AUTOSAR XML (schema 3.1.2)
package /Components/SWC_ProdElEm
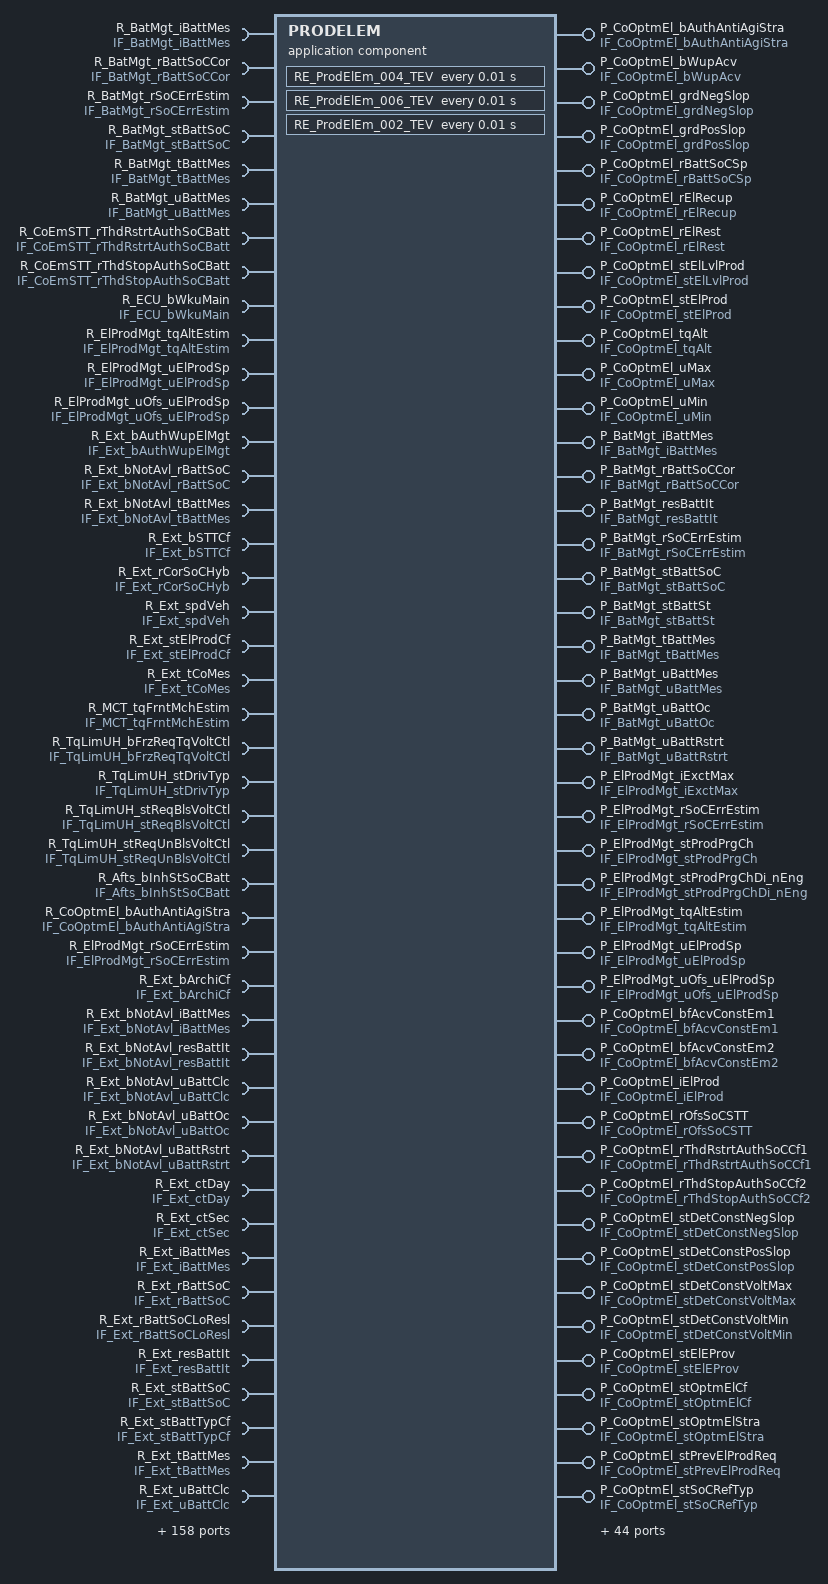
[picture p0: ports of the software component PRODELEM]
  application software component type PRODELEM
    189 x require port:
      R_BatMgt_iBattMes: unqueued-receiver-com-spec{data-element=BatMgt_iBattMes, init-value=ConstantValue, resync-time=0}, required-interface=IF_BatMgt_iBattMes
      R_BatMgt_rBattSoCCor: unqueued-receiver-com-spec{data-element=BatMgt_rBattSoCCor, init-value=ConstantValue1, resync-time=0}, required-interface=IF_BatMgt_rBattSoCCor
      R_BatMgt_rSoCErrEstim: unqueued-receiver-com-spec{data-element=BatMgt_rSoCErrEstim, init-value=BatMgt_rSoCErrEstim_in, resync-time=0}, required-interface=IF_BatMgt_rSoCErrEstim
      R_BatMgt_stBattSoC: unqueued-receiver-com-spec{data-element=BatMgt_stBattSoC, init-value=ConstantValue3, resync-time=0}, required-interface=IF_BatMgt_stBattSoC
      R_BatMgt_tBattMes: unqueued-receiver-com-spec{data-element=BatMgt_tBattMes, init-value=ConstantValue5, resync-time=0}, required-interface=IF_BatMgt_tBattMes
      R_BatMgt_uBattMes: unqueued-receiver-com-spec{data-element=BatMgt_uBattMes, init-value=ConstantValue7, resync-time=0}, required-interface=IF_BatMgt_uBattMes
      R_CoEmSTT_rThdRstrtAuthSoCBatt: unqueued-receiver-com-spec{data-element=CoEmSTT_rThdRstrtAuthSoCBatt, init-value=ConstantValue9, resync-time=0}, required-interface=IF_CoEmSTT_rThdRstrtAuthSoCBatt
      R_CoEmSTT_rThdStopAuthSoCBatt: unqueued-receiver-com-spec{data-element=CoEmSTT_rThdStopAuthSoCBatt, init-value=ConstantValue11, resync-time=0}, required-interface=IF_CoEmSTT_rThdStopAuthSoCBatt
      R_ECU_bWkuMain: unqueued-receiver-com-spec{data-element=ECU_bWkuMain, init-value=ConstantValue13, resync-time=0}, required-interface=IF_ECU_bWkuMain
      R_ElProdMgt_tqAltEstim: unqueued-receiver-com-spec{data-element=ElProdMgt_tqAltEstim, init-value=ElProdMgt_tqAltEstim_in, resync-time=0}, required-interface=IF_ElProdMgt_tqAltEstim
      R_ElProdMgt_uElProdSp: unqueued-receiver-com-spec{data-element=ElProdMgt_uElProdSp, init-value=ElProdMgt_uElProdSp_in, resync-time=0}, required-interface=IF_ElProdMgt_uElProdSp
      R_ElProdMgt_uOfs_uElProdSp: unqueued-receiver-com-spec{data-element=ElProdMgt_uOfs_uElProdSp, init-value=ElProdMgt_uOfs_uElProdSp_in, resync-time=0}, required-interface=IF_ElProdMgt_uOfs_uElProdSp
      R_Ext_bAuthWupElMgt: unqueued-receiver-com-spec{data-element=Ext_bAuthWupElMgt, init-value=Ext_bAuthWupElMgt_in, resync-time=0}, required-interface=IF_Ext_bAuthWupElMgt
      R_Ext_bNotAvl_rBattSoC: unqueued-receiver-com-spec{data-element=Ext_bNotAvl_rBattSoC, init-value=ConstantValue15, resync-time=0}, required-interface=IF_Ext_bNotAvl_rBattSoC
      R_Ext_bNotAvl_tBattMes: unqueued-receiver-com-spec{data-element=Ext_bNotAvl_tBattMes, init-value=ConstantValue17, resync-time=0}, required-interface=IF_Ext_bNotAvl_tBattMes
      R_Ext_bSTTCf: unqueued-receiver-com-spec{data-element=Ext_bSTTCf, init-value=ConstantValue19, resync-time=0}, required-interface=IF_Ext_bSTTCf
      R_Ext_rCorSoCHyb: unqueued-receiver-com-spec{data-element=Ext_rCorSoCHyb, init-value=Ext_rCorSoCHyb_in, resync-time=0}, required-interface=IF_Ext_rCorSoCHyb
      R_Ext_spdVeh: unqueued-receiver-com-spec{data-element=Ext_spdVeh, init-value=ConstantValue21, resync-time=0}, required-interface=IF_Ext_spdVeh
      R_Ext_stElProdCf: unqueued-receiver-com-spec{data-element=Ext_stElProdCf, init-value=ConstantValue23, resync-time=0}, required-interface=IF_Ext_stElProdCf
      R_Ext_tCoMes: unqueued-receiver-com-spec{data-element=Ext_tCoMes, init-value=ConstantValue25, resync-time=0}, required-interface=IF_Ext_tCoMes
      R_MCT_tqFrntMchEstim: unqueued-receiver-com-spec{data-element=MCT_tqFrntMchEstim, init-value=MCT_tqFrntMchEstim_in, resync-time=0}, required-interface=IF_MCT_tqFrntMchEstim
      R_TqLimUH_bFrzReqTqVoltCtl: unqueued-receiver-com-spec{data-element=TqLimUH_bFrzReqTqVoltCtl, init-value=TqLimUH_bFrzReqTqVoltCtl_in, resync-time=0}, required-interface=IF_TqLimUH_bFrzReqTqVoltCtl
      R_TqLimUH_stDrivTyp: unqueued-receiver-com-spec{data-element=TqLimUH_stDrivTyp, init-value=ConstantValue27, resync-time=0}, required-interface=IF_TqLimUH_stDrivTyp
      R_TqLimUH_stReqBlsVoltCtl: unqueued-receiver-com-spec{data-element=TqLimUH_stReqBlsVoltCtl, init-value=TqLimUH_stReqBlsVoltCtl_in, resync-time=0}, required-interface=IF_TqLimUH_stReqBlsVoltCtl
      R_TqLimUH_stReqUnBlsVoltCtl: unqueued-receiver-com-spec{data-element=TqLimUH_stReqUnBlsVoltCtl, init-value=TqLimUH_stReqUnBlsVoltCtl_in, resync-time=0}, required-interface=IF_TqLimUH_stReqUnBlsVoltCtl
      R_Afts_bInhStSoCBatt: unqueued-receiver-com-spec{data-element=Afts_bInhStSoCBatt, init-value=Afts_bInhStSoCBatt_in, resync-time=0}, required-interface=IF_Afts_bInhStSoCBatt
      R_CoOptmEl_bAuthAntiAgiStra: unqueued-receiver-com-spec{data-element=CoOptmEl_bAuthAntiAgiStra, init-value=CoOptmEl_bAuthAntiAgiStra_in, resync-time=0}, required-interface=IF_CoOptmEl_bAuthAntiAgiStra
      R_ElProdMgt_rSoCErrEstim: unqueued-receiver-com-spec{data-element=ElProdMgt_rSoCErrEstim, init-value=ElProdMgt_rSoCErrEstim_in, resync-time=0}, required-interface=IF_ElProdMgt_rSoCErrEstim
      R_Ext_bArchiCf: unqueued-receiver-com-spec{data-element=Ext_bArchiCf, init-value=Ext_bArchiCf_in, resync-time=0}, required-interface=IF_Ext_bArchiCf
      R_Ext_bNotAvl_iBattMes: unqueued-receiver-com-spec{data-element=Ext_bNotAvl_iBattMes, init-value=ConstantValue29, resync-time=0}, required-interface=IF_Ext_bNotAvl_iBattMes
      R_Ext_bNotAvl_resBattIt: unqueued-receiver-com-spec{data-element=Ext_bNotAvl_resBattIt, init-value=ConstantValue31, resync-time=0}, required-interface=IF_Ext_bNotAvl_resBattIt
      R_Ext_bNotAvl_uBattClc: unqueued-receiver-com-spec{data-element=Ext_bNotAvl_uBattClc, init-value=Ext_bNotAvl_uBattClc_in, resync-time=0}, required-interface=IF_Ext_bNotAvl_uBattClc
      R_Ext_bNotAvl_uBattOc: unqueued-receiver-com-spec{data-element=Ext_bNotAvl_uBattOc, init-value=ConstantValue33, resync-time=0}, required-interface=IF_Ext_bNotAvl_uBattOc
      R_Ext_bNotAvl_uBattRstrt: unqueued-receiver-com-spec{data-element=Ext_bNotAvl_uBattRstrt, init-value=Ext_bNotAvl_uBattRstrt_in, resync-time=0}, required-interface=IF_Ext_bNotAvl_uBattRstrt
      R_Ext_ctDay: unqueued-receiver-com-spec{data-element=Ext_ctDay, init-value=Ext_ctDay_in, resync-time=0}, required-interface=IF_Ext_ctDay
      R_Ext_ctSec: unqueued-receiver-com-spec{data-element=Ext_ctSec, init-value=Ext_ctSec_in, resync-time=0}, required-interface=IF_Ext_ctSec
      R_Ext_iBattMes: unqueued-receiver-com-spec{data-element=Ext_iBattMes, init-value=Ext_iBattMes_in, resync-time=0}, required-interface=IF_Ext_iBattMes
      R_Ext_rBattSoC: unqueued-receiver-com-spec{data-element=Ext_rBattSoC, init-value=Ext_rBattSoC_in, resync-time=0}, required-interface=IF_Ext_rBattSoC
      R_Ext_rBattSoCLoResl: unqueued-receiver-com-spec{data-element=Ext_rBattSoCLoResl, init-value=Ext_rBattSoCLoResl_in, resync-time=0}, required-interface=IF_Ext_rBattSoCLoResl
      R_Ext_resBattIt: unqueued-receiver-com-spec{data-element=Ext_resBattIt, init-value=Ext_resBattIt_in, resync-time=0}, required-interface=IF_Ext_resBattIt
      R_Ext_stBattSoC: unqueued-receiver-com-spec{data-element=Ext_stBattSoC, init-value=Ext_stBattSoC_in, resync-time=0}, required-interface=IF_Ext_stBattSoC
      R_Ext_stBattTypCf: unqueued-receiver-com-spec{data-element=Ext_stBattTypCf, init-value=ConstantValue35, resync-time=0}, required-interface=IF_Ext_stBattTypCf
      R_Ext_tBattMes: unqueued-receiver-com-spec{data-element=Ext_tBattMes, init-value=Ext_tBattMes_in, resync-time=0}, required-interface=IF_Ext_tBattMes
      R_Ext_uBattClc: unqueued-receiver-com-spec{data-element=Ext_uBattClc, init-value=Ext_uBattClc_in, resync-time=0}, required-interface=IF_Ext_uBattClc
      R_Ext_uBattMes: unqueued-receiver-com-spec{data-element=Ext_uBattMes, init-value=ConstantValue37, resync-time=0}, required-interface=IF_Ext_uBattMes
      R_Ext_uBattOc: unqueued-receiver-com-spec{data-element=Ext_uBattOc, init-value=Ext_uBattOc_in, resync-time=0}, required-interface=IF_Ext_uBattOc
      R_Ext_uBattRstrt: unqueued-receiver-com-spec{data-element=Ext_uBattRstrt, init-value=Ext_uBattRstrt_in, resync-time=0}, required-interface=IF_Ext_uBattRstrt
      R_Ext_uBattStrt: unqueued-receiver-com-spec{data-element=Ext_uBattStrt, init-value=Ext_uBattStrt_in, resync-time=0}, required-interface=IF_Ext_uBattStrt
      R_CoOptmEl_grdNegSlop: unqueued-receiver-com-spec{data-element=CoOptmEl_grdNegSlop, init-value=CoOptmEl_grdNegSlop_in, resync-time=0}, required-interface=IF_CoOptmEl_grdNegSlop
      R_CoOptmEl_grdPosSlop: unqueued-receiver-com-spec{data-element=CoOptmEl_grdPosSlop, init-value=CoOptmEl_grdPosSlop_in, resync-time=0}, required-interface=IF_CoOptmEl_grdPosSlop
      R_CoOptmEl_rBattSoCSp: unqueued-receiver-com-spec{data-element=CoOptmEl_rBattSoCSp, init-value=CoOptmEl_rBattSoCSp_in, resync-time=0}, required-interface=IF_CoOptmEl_rBattSoCSp
      R_CoOptmEl_uMax: unqueued-receiver-com-spec{data-element=CoOptmEl_uMax, init-value=CoOptmEl_uMax_in, resync-time=0}, required-interface=IF_CoOptmEl_uMax
      R_TqLimUH_grdLimVoltCtlDynMax: unqueued-receiver-com-spec{data-element=TqLimUH_grdLimVoltCtlDynMax, init-value=TqLimUH_grdLimVoltCtlDynMax_in, resync-time=0}, required-interface=IF_TqLimUH_grdLimVoltCtlDynMax
      R_AccP_rAccP: unqueued-receiver-com-spec{data-element=AccP_rAccP, init-value=ConstantValue39, resync-time=0}, required-interface=IF_AccP_rAccP
      R_BatMgt_bBattAntiAgiAcvReq: unqueued-receiver-com-spec{data-element=BatMgt_bBattAntiAgiAcvReq, init-value=BatMgt_bBattAntiAgiAcvReq_in, resync-time=0}, required-interface=IF_BatMgt_bBattAntiAgiAcvReq
      R_BatMgt_bBattChProtAcvReq: unqueued-receiver-com-spec{data-element=BatMgt_bBattChProtAcvReq, init-value=BatMgt_bBattChProtAcvReq_in, resync-time=0}, required-interface=IF_BatMgt_bBattChProtAcvReq
      R_BatMgt_bBattSoCMinProtAcvReq: unqueued-receiver-com-spec{data-element=BatMgt_bBattSoCMinProtAcvReq, init-value=BatMgt_bBattSoCMinProtAcvReq_in, resync-time=0}, required-interface=IF_BatMgt_bBattSoCMinProtAcvReq
      R_BatMgt_bBattStopPrepAcvReq: unqueued-receiver-com-spec{data-element=BatMgt_bBattStopPrepAcvReq, init-value=BatMgt_bBattStopPrepAcvReq_in, resync-time=0}, required-interface=IF_BatMgt_bBattStopPrepAcvReq
      R_BatMgt_bBattTProtAcvReq: unqueued-receiver-com-spec{data-element=BatMgt_bBattTProtAcvReq, init-value=BatMgt_bBattTProtAcvReq_in, resync-time=0}, required-interface=IF_BatMgt_bBattTProtAcvReq
      R_BatMgt_grdNegSlopBattAntiAgi: unqueued-receiver-com-spec{data-element=BatMgt_grdNegSlopBattAntiAgi, init-value=BatMgt_grdNegSlopBattAntiAgi_in, resync-time=0}, required-interface=IF_BatMgt_grdNegSlopBattAntiAgi
      R_BatMgt_grdNegSlopBattTProt: unqueued-receiver-com-spec{data-element=BatMgt_grdNegSlopBattTProt, init-value=BatMgt_grdNegSlopBattTProt_in, resync-time=0}, required-interface=IF_BatMgt_grdNegSlopBattTProt
      R_BatMgt_grdPosSlopBattAntiAgi: unqueued-receiver-com-spec{data-element=BatMgt_grdPosSlopBattAntiAgi, init-value=BatMgt_grdPosSlopBattAntiAgi_in, resync-time=0}, required-interface=IF_BatMgt_grdPosSlopBattAntiAgi
      R_BatMgt_grdPosSlopBattTProt: unqueued-receiver-com-spec{data-element=BatMgt_grdPosSlopBattTProt, init-value=BatMgt_grdPosSlopBattTProt_in, resync-time=0}, required-interface=IF_BatMgt_grdPosSlopBattTProt
      R_BatMgt_rOfsSoC: unqueued-receiver-com-spec{data-element=BatMgt_rOfsSoC, init-value=BatMgt_rOfsSoC_in, resync-time=0}, required-interface=IF_BatMgt_rOfsSoC
      R_BatMgt_stBattSoH: unqueued-receiver-com-spec{data-element=BatMgt_stBattSoH, init-value=ConstantValue41, resync-time=0}, required-interface=IF_BatMgt_stBattSoH
      R_BatMgt_uReqEmMaxBattAntiAgi: unqueued-receiver-com-spec{data-element=BatMgt_uReqEmMaxBattAntiAgi, init-value=BatMgt_uReqEmMaxBattAntiAgi_in, resync-time=0}, required-interface=IF_BatMgt_uReqEmMaxBattAntiAgi
      R_BatMgt_uReqEmMaxBattTProt: unqueued-receiver-com-spec{data-element=BatMgt_uReqEmMaxBattTProt, init-value=BatMgt_uReqEmMaxBattTProt_in, resync-time=0}, required-interface=IF_BatMgt_uReqEmMaxBattTProt
      R_BatMgt_uReqEmMinBattAntiAgi: unqueued-receiver-com-spec{data-element=BatMgt_uReqEmMinBattAntiAgi, init-value=BatMgt_uReqEmMinBattAntiAgi_in, resync-time=0}, required-interface=IF_BatMgt_uReqEmMinBattAntiAgi
      R_BatMgt_uReqEmMinBattTProt: unqueued-receiver-com-spec{data-element=BatMgt_uReqEmMinBattTProt, init-value=BatMgt_uReqEmMinBattTProt_in, resync-time=0}, required-interface=IF_BatMgt_uReqEmMinBattTProt
      R_CoEmCkg_stStrtRstrtFbCmd: unqueued-receiver-com-spec{data-element=CoEmCkg_stStrtRstrtFbCmd, init-value=ConstantValue43, resync-time=0}, required-interface=IF_CoEmCkg_stStrtRstrtFbCmd
      R_CoEmSTT_bVSSAcvSt: unqueued-receiver-com-spec{data-element=CoEmSTT_bVSSAcvSt, init-value=ConstantValue45, resync-time=0}, required-interface=IF_CoEmSTT_bVSSAcvSt
      R_CoEmSTT_iElNwStop: unqueued-receiver-com-spec{data-element=CoEmSTT_iElNwStop, init-value=ConstantValue47, resync-time=0}, required-interface=IF_CoEmSTT_iElNwStop
      R_CoEmSTT_rThdStopAuthSoCCf1: unqueued-receiver-com-spec{data-element=CoEmSTT_rThdStopAuthSoCCf1, init-value=ConstantValue49, resync-time=0}, required-interface=IF_CoEmSTT_rThdStopAuthSoCCf1
      R_CoPt_noEgdGearCord: unqueued-receiver-com-spec{data-element=CoPt_noEgdGearCord, init-value=ConstantValue51, resync-time=0}, required-interface=IF_CoPt_noEgdGearCord
      R_CoPtSynt_stPwt: unqueued-receiver-com-spec{data-element=CoPtSynt_stPwt, init-value=ConstantValue53, resync-time=0}, required-interface=IF_CoPtSynt_stPwt
      R_CoPtUH_stTypSTTNotAvl: unqueued-receiver-com-spec{data-element=CoPtUH_stTypSTTNotAvl, init-value=ConstantValue55, resync-time=0}, required-interface=IF_CoPtUH_stTypSTTNotAvl
      R_CoStrtRStrt_stAcvReq: unqueued-receiver-com-spec{data-element=CoStrtRStrt_stAcvReq, init-value=CoStrtRStrt_stAcvReq_in, resync-time=0}, required-interface=IF_CoStrtRStrt_stAcvReq
      R_ElecMgt_stPrioVoltMax: unqueued-receiver-com-spec{data-element=ElecMgt_stPrioVoltMax, init-value=ElecMgt_stPrioVoltMax_in, resync-time=0}, required-interface=IF_ElecMgt_stPrioVoltMax
      R_ElecMgt_stPrioVoltMin: unqueued-receiver-com-spec{data-element=ElecMgt_stPrioVoltMin, init-value=ElecMgt_stPrioVoltMin_in, resync-time=0}, required-interface=IF_ElecMgt_stPrioVoltMin
      R_ElecMgt_uReqProdMax: unqueued-receiver-com-spec{data-element=ElecMgt_uReqProdMax, init-value=ElecMgt_uReqProdMax_in, resync-time=0}, required-interface=IF_ElecMgt_uReqProdMax
      R_ElecMgt_uReqProdMin: unqueued-receiver-com-spec{data-element=ElecMgt_uReqProdMin, init-value=ElecMgt_uReqProdMin_in, resync-time=0}, required-interface=IF_ElecMgt_uReqProdMin
      R_ElecMgt_uReqProdSlope: unqueued-receiver-com-spec{data-element=ElecMgt_uReqProdSlope, init-value=ElecMgt_uReqProdSlope_in, resync-time=0}, required-interface=IF_ElecMgt_uReqProdSlope
      R_ElProdMgt_bAcvCoefFilDftAlt: unqueued-receiver-com-spec{data-element=ElProdMgt_bAcvCoefFilDftAlt, init-value=ElProdMgt_bAcvCoefFilDftAlt_in, resync-time=0}, required-interface=IF_ElProdMgt_bAcvCoefFilDftAlt
      R_ElProdMgt_iAltEstim: unqueued-receiver-com-spec{data-element=ElProdMgt_iAltEstim, init-value=ElProdMgt_iAltEstim_in, resync-time=0}, required-interface=IF_ElProdMgt_iAltEstim
      R_Eng_nCkFil: unqueued-receiver-com-spec{data-element=Eng_nCkFil, init-value=ConstantValue57, resync-time=0}, required-interface=IF_Eng_nCkFil
      R_Ext_bfAcvConstElMgt{1..3}: unqueued-receiver-com-spec{data-element=Ext_bfAcvConstElMgt{1..3}, init-value=Ext_bfAcvConstElMgt{1..3}_in, resync-time=0}, required-interface=IF_Ext_bfAcvConstElMgt{1..3}
      R_Ext_bfAcvConstEng1: unqueued-receiver-com-spec{data-element=Ext_bfAcvConstEng1, init-value=Ext_bfAcvConstEng1_in, resync-time=0}, required-interface=IF_Ext_bfAcvConstEng1
      R_Ext_bfAcvConstReTra1: unqueued-receiver-com-spec{data-element=Ext_bfAcvConstReTra1, init-value=Ext_bfAcvConstReTra1_in, resync-time=0}, required-interface=IF_Ext_bfAcvConstReTra1
      R_Ext_dstVehTotMes: unqueued-receiver-com-spec{data-element=Ext_dstVehTotMes, init-value=ConstantValue59, resync-time=0}, required-interface=IF_Ext_dstVehTotMes
      R_Ext_stAltClasCf: unqueued-receiver-com-spec{data-element=Ext_stAltClasCf, init-value=Ext_stAltClasCf_in, resync-time=0}, required-interface=IF_Ext_stAltClasCf
      R_Ext_stVSSCf: unqueued-receiver-com-spec{data-element=Ext_stVSSCf, init-value=ConstantValue61, resync-time=0}, required-interface=IF_Ext_stVSSCf
      R_RvAltMgt_iRvAltGenModEstim: unqueued-receiver-com-spec{data-element=RvAltMgt_iRvAltGenModEstim, init-value=RvAltMgt_iRvAltGenModEstim_in, resync-time=0}, required-interface=IF_RvAltMgt_iRvAltGenModEstim
      R_RvAltMgt_tqRvAltGenModEstim: unqueued-receiver-com-spec{data-element=RvAltMgt_tqRvAltGenModEstim, init-value=RvAltMgt_tqRvAltGenModEstim_in, resync-time=0}, required-interface=IF_RvAltMgt_tqRvAltGenModEstim
      R_RvAltMgt_tRvAltECUMes: unqueued-receiver-com-spec{data-element=RvAltMgt_tRvAltECUMes, init-value=RvAltMgt_tRvAltECUMes_in, resync-time=0}, required-interface=IF_RvAltMgt_tRvAltECUMes
      R_StopStrtEng_stCdnNxtCkg: unqueued-receiver-com-spec{data-element=StopStrtEng_stCdnNxtCkg, init-value=ConstantValue63, resync-time=0}, required-interface=IF_StopStrtEng_stCdnNxtCkg
      R_TqDem_bTqGrdLim: unqueued-receiver-com-spec{data-element=TqDem_bTqGrdLim, init-value=TqDem_bTqGrdLim_in, resync-time=0}, required-interface=IF_TqDem_bTqGrdLim
      R_Afts_bLrnRstReq_rOfsSoC: unqueued-receiver-com-spec{data-element=Afts_bLrnRstReq_rOfsSoC, init-value=Afts_bLrnRstReq_rOfsSoC_in, resync-time=0}, required-interface=IF_Afts_bLrnRstReq_rOfsSoC
      R_Afts_bRstReq_stSoHBatt: unqueued-receiver-com-spec{data-element=Afts_bRstReq_stSoHBatt, init-value=Afts_bRstReq_stSoHBatt_in, resync-time=0}, required-interface=IF_Afts_bRstReq_stSoHBatt
      R_Afts_bRstReqStcBatt: unqueued-receiver-com-spec{data-element=Afts_bRstReqStcBatt, init-value=Afts_bRstReqStcBatt_in, resync-time=0}, required-interface=IF_Afts_bRstReqStcBatt
      R_CoOptmEl_stOptmElCf: unqueued-receiver-com-spec{data-element=CoOptmEl_stOptmElCf, init-value=CoOptmEl_stOptmElCf_in, resync-time=0}, required-interface=IF_CoOptmEl_stOptmElCf
      R_CoOptmEl_stStraVoltBatt: unqueued-receiver-com-spec{data-element=CoOptmEl_stStraVoltBatt, init-value=CoOptmEl_stStraVoltBatt_in, resync-time=0}, required-interface=IF_CoOptmEl_stStraVoltBatt
      R_CoOptmEl_tiLdSoCAuthStop: unqueued-receiver-com-spec{data-element=CoOptmEl_tiLdSoCAuthStop, init-value=CoOptmEl_tiLdSoCAuthStop_in, resync-time=0}, required-interface=IF_CoOptmEl_tiLdSoCAuthStop
      R_ElProdMgt_uBattSp: unqueued-receiver-com-spec{data-element=ElProdMgt_uBattSp, init-value=ElProdMgt_uBattSp_in, resync-time=0}, required-interface=IF_ElProdMgt_uBattSp
      R_Ext_bNotAvl_rBattSoCLoResl: unqueued-receiver-com-spec{data-element=Ext_bNotAvl_rBattSoCLoResl, init-value=Ext_bNotAvl_rBattSoCLoResl_in, resync-time=0}, required-interface=IF_Ext_bNotAvl_rBattSoCLoResl
      R_Ext_bNotAvl_uBattStrt: unqueued-receiver-com-spec{data-element=Ext_bNotAvl_uBattStrt, init-value=Ext_bNotAvl_uBattStrt_in, resync-time=0}, required-interface=IF_Ext_bNotAvl_uBattStrt
      R_Ext_ctYr: unqueued-receiver-com-spec{data-element=Ext_ctYr, init-value=Ext_ctYr_in, resync-time=0}, required-interface=IF_Ext_ctYr
      R_RvAltMgt_uRvAltMes: unqueued-receiver-com-spec{data-element=RvAltMgt_uRvAltMes, init-value=RvAltMgt_uRvAltMes_in, resync-time=0}, required-interface=IF_RvAltMgt_uRvAltMes
      R_CoOptmEl_stPrevElProdReq: unqueued-receiver-com-spec{data-element=CoOptmEl_stPrevElProdReq, init-value=CoOptmEl_stPrevElProdReq_in, resync-time=0}, required-interface=IF_CoOptmEl_stPrevElProdReq
      R_CoOptmEl_uMinInc: unqueued-receiver-com-spec{data-element=CoOptmEl_uMinInc, init-value=CoOptmEl_uMinInc_in, resync-time=0}, required-interface=IF_CoOptmEl_uMinInc
      R_Ext_facRatTqAltCf: unqueued-receiver-com-spec{data-element=Ext_facRatTqAltCf, init-value=Ext_facRatTqAltCf_in, resync-time=0}, required-interface=IF_Ext_facRatTqAltCf
      R_Ext_iAltExct: unqueued-receiver-com-spec{data-element=Ext_iAltExct, init-value=Ext_iAltExct_in, resync-time=0}, required-interface=IF_Ext_iAltExct
      R_RvAltMgt_nRvAltMes: unqueued-receiver-com-spec{data-element=RvAltMgt_nRvAltMes, init-value=ConstantValue65, resync-time=0}, required-interface=IF_RvAltMgt_nRvAltMes
      R_BatMgt_uReqEmMinBattChProt: unqueued-receiver-com-spec{data-element=BatMgt_uReqEmMinBattChProt, init-value=BatMgt_uReqEmMinBattChProt_in, resync-time=0}, required-interface=IF_BatMgt_uReqEmMinBattChProt
      R_BatMgt_uReqEmMaxBattChProt: unqueued-receiver-com-spec{data-element=BatMgt_uReqEmMaxBattChProt, init-value=BatMgt_uReqEmMaxBattChProt_in, resync-time=0}, required-interface=IF_BatMgt_uReqEmMaxBattChProt
      R_BatMgt_grdPosSlopBattChProt: unqueued-receiver-com-spec{data-element=BatMgt_grdPosSlopBattChProt, init-value=BatMgt_grdPosSlopBattChProt_in, resync-time=0}, required-interface=IF_BatMgt_grdPosSlopBattChProt
      R_BatMgt_grdNegSlopBattChProt: unqueued-receiver-com-spec{data-element=BatMgt_grdNegSlopBattChProt, init-value=BatMgt_grdNegSlopBattChProt_in, resync-time=0}, required-interface=IF_BatMgt_grdNegSlopBattChProt
      R_CoPtUH_bTestPrvtBltAcv: unqueued-receiver-com-spec{data-element=CoPtUH_bTestPrvtBltAcv, init-value=ConstantValue67, resync-time=0}, required-interface=IF_CoPtUH_bTestPrvtBltAcv
      R_CoStrtRStrt_stEngStrtReq: unqueued-receiver-com-spec{data-element=CoStrtRStrt_stEngStrtReq, init-value=ConstantValue69, resync-time=0}, required-interface=IF_CoStrtRStrt_stEngStrtReq
      R_ElProdMgt_uOfsLossCor: unqueued-receiver-com-spec{data-element=ElProdMgt_uOfsLossCor, init-value=ElProdMgt_uOfsLossCor_in, resync-time=0}, required-interface=IF_ElProdMgt_uOfsLossCor
      R_Ext_rAltCycOp: unqueued-receiver-com-spec{data-element=Ext_rAltCycOp, init-value=ConstantValue71, resync-time=0}, required-interface=IF_Ext_rAltCycOp
      R_RvAltMgt_stRvAltModReq: unqueued-receiver-com-spec{data-element=RvAltMgt_stRvAltModReq, init-value=RvAltMgt_stRvAltModReq_in, resync-time=0}, required-interface=IF_RvAltMgt_stRvAltModReq
      R_CoOptmEl_stOptmElStra: unqueued-receiver-com-spec{data-element=CoOptmEl_stOptmElStra, init-value=CoOptmEl_stOptmElStra_in, resync-time=0}, required-interface=IF_CoOptmEl_stOptmElStra
      R_Ext_iBattMaxCkg: unqueued-receiver-com-spec{data-element=Ext_iBattMaxCkg, init-value=Ext_iBattMaxCkg_in, resync-time=0}, required-interface=IF_Ext_iBattMaxCkg
      R_Ext_resBattItNorm: unqueued-receiver-com-spec{data-element=Ext_resBattItNorm, init-value=Ext_resBattItNorm_in, resync-time=0}, required-interface=IF_Ext_resBattItNorm
      R_Ext_uBattMinCkg: unqueued-receiver-com-spec{data-element=Ext_uBattMinCkg, init-value=Ext_uBattMinCkg_in, resync-time=0}, required-interface=IF_Ext_uBattMinCkg
      R_CoOptmEl_iElNw: unqueued-receiver-com-spec{data-element=CoOptmEl_iElNw, init-value=CoOptmEl_iElNw_in, resync-time=0}, required-interface=IF_CoOptmEl_iElNw
      R_Ext_idxCtlAltProvIdf: unqueued-receiver-com-spec{data-element=Ext_idxCtlAltProvIdf, init-value=Ext_idxCtlAltProvIdf_in, resync-time=0}, required-interface=IF_Ext_idxCtlAltProvIdf
      R_RvAltMgt_bIdcVldCurGenMod: unqueued-receiver-com-spec{data-element=RvAltMgt_bIdcVldCurGenMod, init-value=RvAltMgt_bIdcVldCurGenMod_in, resync-time=0}, required-interface=IF_RvAltMgt_bIdcVldCurGenMod
      R_CoOptmEl_iElProdMaxLdBatt: unqueued-receiver-com-spec{data-element=CoOptmEl_iElProdMaxLdBatt, init-value=CoOptmEl_iElProdMaxLdBatt_in, resync-time=0}, required-interface=IF_CoOptmEl_iElProdMaxLdBatt
      R_Ext_tAir: unqueued-receiver-com-spec{data-element=Ext_tAir, init-value=ConstantValue73, resync-time=0}, required-interface=IF_Ext_tAir
      R_TqLimUH_bfAcvConstFrntTra1: unqueued-receiver-com-spec{data-element=TqLimUH_bfAcvConstFrntTra1, init-value=TqLimUH_bfAcvConstFrntTra1_in, resync-time=0}, required-interface=IF_TqLimUH_bfAcvConstFrntTra1
      R_VSSCtzMgt_bAcvElCnsReq: unqueued-receiver-com-spec{data-element=VSSCtzMgt_bAcvElCnsReq, init-value=VSSCtzMgt_bAcvElCnsReq_in, resync-time=0}, required-interface=IF_VSSCtzMgt_bAcvElCnsReq
      R_CoOptmEl_stPrgChReq: unqueued-receiver-com-spec{data-element=CoOptmEl_stPrgChReq, init-value=CoOptmEl_stPrgChReq_in, resync-time=0}, required-interface=IF_CoOptmEl_stPrgChReq
      R_FRM_bAcvCoOptmElDftLvlProd: required-interface=FunctionInhibition
      R_FRM_bAcvCoOptmElDftSoC: required-interface=FunctionInhibition
      R_FRM_bAcvCoOptmElSatLvlProd: required-interface=FunctionInhibition
      R_FRM_bInhCoOptmElElMgtReq: required-interface=FunctionInhibition
      R_FRM_bInhCoOptmElEngReq: required-interface=FunctionInhibition
      R_FRM_bInhCoOptmElFrntTraReq: required-interface=FunctionInhibition
      R_FRM_bInhCoOptmElFrzLvlProd: required-interface=FunctionInhibition
      R_FRM_bInhCoOptmElReTraReq: required-interface=FunctionInhibition
      R_FRM_bInhCoOptmElStra_tAirExt: required-interface=FunctionInhibition
      R_FRM_bInhCoOptmElTHom_tAirExt: required-interface=FunctionInhibition
      R_FRM_bInhCoOptmElTHom_tBatt: required-interface=FunctionInhibition
      R_FRM_bInhCoOptmElWup_tBatt: required-interface=FunctionInhibition
      R_FRM_bInhCoOptmElWupElMgt: required-interface=FunctionInhibition
      R_FRM_bAcvBatMgtDftValStBatt: required-interface=FunctionInhibition
      R_FRM_bInhBatMgtSoCClc: required-interface=FunctionInhibition
      R_FRM_bInhBatMgtTestCohVolt: required-interface=FunctionInhibition
      R_FRM_bInhElProdMgtCorVoltSp: required-interface=FunctionInhibition
      R_FRM_bAcvCoOptmEl_tBatt: required-interface=FunctionInhibition
      R_FRM_bAcvCoOptmEl_tCo: required-interface=FunctionInhibition
      R_FRM_bAcvCoOptmElBattElEProv: required-interface=FunctionInhibition
      R_FRM_bAcvCoOptmElProdElEProv: required-interface=FunctionInhibition
      R_FRM_bAcvCoOptmElSlopStra: required-interface=FunctionInhibition
      R_FRM_bAcvCoOptmElSoCSpDftVal: required-interface=FunctionInhibition
      R_FRM_bInhCoOptmElBackUpStra: required-interface=FunctionInhibition
      R_FRM_bInhCoOptmElBlsProd: required-interface=FunctionInhibition
      R_FRM_bInhCoOptmElCurAuxEstim: required-interface=FunctionInhibition
      R_FRM_bInhCoOptmElRvAltLoss: required-interface=FunctionInhibition
      R_FRM_bInhCoOptmElTHom_iBatt: required-interface=FunctionInhibition
      R_FRM_bInhCoOptmElTHom_spdVeh: required-interface=FunctionInhibition
      R_FRM_bInhCoOptmElTHomElMgt: required-interface=FunctionInhibition
      R_FRM_bInhBatMgt_uBattRstrt: required-interface=FunctionInhibition
      R_FRM_bInhBatMgtBattNotConn: required-interface=FunctionInhibition
      R_FRM_bInhBatMgtCurBattMes: required-interface=FunctionInhibition
      R_FRM_bInhBatMgtKmAntiAgi: required-interface=FunctionInhibition
      R_FRM_bInhBatMgtPerAntiAgi: required-interface=FunctionInhibition
      R_FRM_bInhBatMgtSoH: required-interface=FunctionInhibition
      R_FRM_bInhBatMgtStSoCAfts: required-interface=FunctionInhibition
      R_FRM_bInhBatMgtTBattMes: required-interface=FunctionInhibition
      R_FRM_bInhBatMgtTiAntiAgi: required-interface=FunctionInhibition
      R_FRM_bInhBatMgtVoltBattClc: required-interface=FunctionInhibition
      R_FRM_bAcvElProdMgtStraDftCom: required-interface=FunctionInhibition
      R_FRM_bAcvElProdMgtStraDftEl: required-interface=FunctionInhibition
      R_FRM_bAcvElProdMgtStraDftMec: required-interface=FunctionInhibition
      R_FRM_bInhElProdMgtAltOfsSpMes: required-interface=FunctionInhibition
      R_FRM_bInhElProdMgtAltProvIdf: required-interface=FunctionInhibition
      R_FRM_bInhElProdMgtAltVoltSp: required-interface=FunctionInhibition
      R_FRM_bInhElProdMgtCorOfsLoss: required-interface=FunctionInhibition
      R_FRM_bInhElProdMgtDiagCorLoss: required-interface=FunctionInhibition
      R_FRM_bInhElProdMgtTqAltLoss: required-interface=FunctionInhibition
      R_FRM_bInhCoOptmElElMgtOldReq: required-interface=FunctionInhibition
      R_FRM_bInhBatMgtDiagSoC: required-interface=FunctionInhibition
      R_FRM_bInhBatMgtOfsSoC: required-interface=FunctionInhibition
      R_FRM_bInhBatMgtStcBattSoC: required-interface=FunctionInhibition
      R_FRM_bAcvCoOptmElMinSoCReq: required-interface=FunctionInhibition
    85 x provide port:
      P_CoOptmEl_bAuthAntiAgiStra: unqueued-sender-com-spec{data-element=CoOptmEl_bAuthAntiAgiStra, can-invalidate=false, init-value=CoOptmEl_bAuthAntiAgiStra_out}, provided-interface=IF_CoOptmEl_bAuthAntiAgiStra
      P_CoOptmEl_bWupAcv: unqueued-sender-com-spec{data-element=CoOptmEl_bWupAcv, can-invalidate=false, init-value=CoOptmEl_bWupAcv_out}, provided-interface=IF_CoOptmEl_bWupAcv
      P_CoOptmEl_grdNegSlop: unqueued-sender-com-spec{data-element=CoOptmEl_grdNegSlop, can-invalidate=false, init-value=CoOptmEl_grdNegSlop_out}, provided-interface=IF_CoOptmEl_grdNegSlop
      P_CoOptmEl_grdPosSlop: unqueued-sender-com-spec{data-element=CoOptmEl_grdPosSlop, can-invalidate=false, init-value=CoOptmEl_grdPosSlop_out}, provided-interface=IF_CoOptmEl_grdPosSlop
      P_CoOptmEl_rBattSoCSp: unqueued-sender-com-spec{data-element=CoOptmEl_rBattSoCSp, can-invalidate=false, init-value=CoOptmEl_rBattSoCSp_out}, provided-interface=IF_CoOptmEl_rBattSoCSp
      P_CoOptmEl_rElRecup: unqueued-sender-com-spec{data-element=CoOptmEl_rElRecup, can-invalidate=false, init-value=CoOptmEl_rElRecup_out}, provided-interface=IF_CoOptmEl_rElRecup
      P_CoOptmEl_rElRest: unqueued-sender-com-spec{data-element=CoOptmEl_rElRest, can-invalidate=false, init-value=CoOptmEl_rElRest_out}, provided-interface=IF_CoOptmEl_rElRest
      P_CoOptmEl_stElLvlProd: unqueued-sender-com-spec{data-element=CoOptmEl_stElLvlProd, can-invalidate=false, init-value=CoOptmEl_stElLvlProd_out}, provided-interface=IF_CoOptmEl_stElLvlProd
      P_CoOptmEl_stElProd: unqueued-sender-com-spec{data-element=CoOptmEl_stElProd, can-invalidate=false, init-value=CoOptmEl_stElProd_out}, provided-interface=IF_CoOptmEl_stElProd
      P_CoOptmEl_tqAlt: unqueued-sender-com-spec{data-element=CoOptmEl_tqAlt, can-invalidate=false, init-value=ConstantValue75}, provided-interface=IF_CoOptmEl_tqAlt
      P_CoOptmEl_uMax: unqueued-sender-com-spec{data-element=CoOptmEl_uMax, can-invalidate=false, init-value=CoOptmEl_uMax_out}, provided-interface=IF_CoOptmEl_uMax
      P_CoOptmEl_uMin: unqueued-sender-com-spec{data-element=CoOptmEl_uMin, can-invalidate=false, init-value=CoOptmEl_uMin_out}, provided-interface=IF_CoOptmEl_uMin
      P_BatMgt_iBattMes: unqueued-sender-com-spec{data-element=BatMgt_iBattMes, can-invalidate=false, init-value=ConstantValue}, provided-interface=IF_BatMgt_iBattMes
      P_BatMgt_rBattSoCCor: unqueued-sender-com-spec{data-element=BatMgt_rBattSoCCor, can-invalidate=false, init-value=ConstantValue77}, provided-interface=IF_BatMgt_rBattSoCCor
      P_BatMgt_resBattIt: unqueued-sender-com-spec{data-element=BatMgt_resBattIt, can-invalidate=false, init-value=ConstantValue79}, provided-interface=IF_BatMgt_resBattIt
      P_BatMgt_rSoCErrEstim: unqueued-sender-com-spec{data-element=BatMgt_rSoCErrEstim, can-invalidate=false, init-value=BatMgt_rSoCErrEstim_out}, provided-interface=IF_BatMgt_rSoCErrEstim
      P_BatMgt_stBattSoC: unqueued-sender-com-spec{data-element=BatMgt_stBattSoC, can-invalidate=false, init-value=ConstantValue81}, provided-interface=IF_BatMgt_stBattSoC
      P_BatMgt_stBattSt: unqueued-sender-com-spec{data-element=BatMgt_stBattSt, can-invalidate=false, init-value=BatMgt_stBattSt_out}, provided-interface=IF_BatMgt_stBattSt
      P_BatMgt_tBattMes: unqueued-sender-com-spec{data-element=BatMgt_tBattMes, can-invalidate=false, init-value=ConstantValue83}, provided-interface=IF_BatMgt_tBattMes
      P_BatMgt_uBattMes: unqueued-sender-com-spec{data-element=BatMgt_uBattMes, can-invalidate=false, init-value=ConstantValue85}, provided-interface=IF_BatMgt_uBattMes
      P_BatMgt_uBattOc: unqueued-sender-com-spec{data-element=BatMgt_uBattOc, can-invalidate=false, init-value=ConstantValue87}, provided-interface=IF_BatMgt_uBattOc
      P_BatMgt_uBattRstrt: unqueued-sender-com-spec{data-element=BatMgt_uBattRstrt, can-invalidate=false, init-value=ConstantValue89}, provided-interface=IF_BatMgt_uBattRstrt
      P_ElProdMgt_iExctMax: unqueued-sender-com-spec{data-element=ElProdMgt_iExctMax, can-invalidate=false, init-value=ElProdMgt_iExctMax_out}, provided-interface=IF_ElProdMgt_iExctMax
      P_ElProdMgt_rSoCErrEstim: unqueued-sender-com-spec{data-element=ElProdMgt_rSoCErrEstim, can-invalidate=false, init-value=ElProdMgt_rSoCErrEstim_out}, provided-interface=IF_ElProdMgt_rSoCErrEstim
      P_ElProdMgt_stProdPrgCh: unqueued-sender-com-spec{data-element=ElProdMgt_stProdPrgCh, can-invalidate=false, init-value=ElProdMgt_stProdPrgCh_out}, provided-interface=IF_ElProdMgt_stProdPrgCh
      P_ElProdMgt_stProdPrgChDi_nEng: unqueued-sender-com-spec{data-element=ElProdMgt_stProdPrgChDi_nEng, can-invalidate=false, init-value=ElProdMgt_stProdPrgChDi_nEng_out}, provided-interface=IF_ElProdMgt_stProdPrgChDi_nEng
      P_ElProdMgt_tqAltEstim: unqueued-sender-com-spec{data-element=ElProdMgt_tqAltEstim, can-invalidate=false, init-value=ElProdMgt_tqAltEstim_out}, provided-interface=IF_ElProdMgt_tqAltEstim
      P_ElProdMgt_uElProdSp: unqueued-sender-com-spec{data-element=ElProdMgt_uElProdSp, can-invalidate=false, init-value=ElProdMgt_uElProdSp_out}, provided-interface=IF_ElProdMgt_uElProdSp
      P_ElProdMgt_uOfs_uElProdSp: unqueued-sender-com-spec{data-element=ElProdMgt_uOfs_uElProdSp, can-invalidate=false, init-value=ElProdMgt_uOfs_uElProdSp_out}, provided-interface=IF_ElProdMgt_uOfs_uElProdSp
      P_CoOptmEl_bfAcvConstEm1: unqueued-sender-com-spec{data-element=CoOptmEl_bfAcvConstEm1, can-invalidate=false, init-value=CoOptmEl_bfAcvConstEm1_out}, provided-interface=IF_CoOptmEl_bfAcvConstEm1
      P_CoOptmEl_bfAcvConstEm2: unqueued-sender-com-spec{data-element=CoOptmEl_bfAcvConstEm2, can-invalidate=false, init-value=CoOptmEl_bfAcvConstEm2_out}, provided-interface=IF_CoOptmEl_bfAcvConstEm2
      P_CoOptmEl_iElProd: unqueued-sender-com-spec{data-element=CoOptmEl_iElProd, can-invalidate=false, init-value=ConstantValue91}, provided-interface=IF_CoOptmEl_iElProd
      P_CoOptmEl_rOfsSoCSTT: unqueued-sender-com-spec{data-element=CoOptmEl_rOfsSoCSTT, can-invalidate=false, init-value=ConstantValue93}, provided-interface=IF_CoOptmEl_rOfsSoCSTT
      P_CoOptmEl_rThdRstrtAuthSoCCf1: unqueued-sender-com-spec{data-element=CoOptmEl_rThdRstrtAuthSoCCf1, can-invalidate=false, init-value=ConstantValue95}, provided-interface=IF_CoOptmEl_rThdRstrtAuthSoCCf1
      P_CoOptmEl_rThdStopAuthSoCCf2: unqueued-sender-com-spec{data-element=CoOptmEl_rThdStopAuthSoCCf2, can-invalidate=false, init-value=ConstantValue97}, provided-interface=IF_CoOptmEl_rThdStopAuthSoCCf2
      P_CoOptmEl_stDetConstNegSlop: unqueued-sender-com-spec{data-element=CoOptmEl_stDetConstNegSlop, can-invalidate=false, init-value=CoOptmEl_stDetConstNegSlop_out}, provided-interface=IF_CoOptmEl_stDetConstNegSlop
      P_CoOptmEl_stDetConstPosSlop: unqueued-sender-com-spec{data-element=CoOptmEl_stDetConstPosSlop, can-invalidate=false, init-value=CoOptmEl_stDetConstPosSlop_out}, provided-interface=IF_CoOptmEl_stDetConstPosSlop
      P_CoOptmEl_stDetConstVoltMax: unqueued-sender-com-spec{data-element=CoOptmEl_stDetConstVoltMax, can-invalidate=false, init-value=CoOptmEl_stDetConstVoltMax_out}, provided-interface=IF_CoOptmEl_stDetConstVoltMax
      P_CoOptmEl_stDetConstVoltMin: unqueued-sender-com-spec{data-element=CoOptmEl_stDetConstVoltMin, can-invalidate=false, init-value=CoOptmEl_stDetConstVoltMin_out}, provided-interface=IF_CoOptmEl_stDetConstVoltMin
      P_CoOptmEl_stElEProv: unqueued-sender-com-spec{data-element=CoOptmEl_stElEProv, can-invalidate=false, init-value=ConstantValue99}, provided-interface=IF_CoOptmEl_stElEProv
      P_CoOptmEl_stOptmElCf: unqueued-sender-com-spec{data-element=CoOptmEl_stOptmElCf, can-invalidate=false, init-value=CoOptmEl_stOptmElCf_out}, provided-interface=IF_CoOptmEl_stOptmElCf
      P_CoOptmEl_stOptmElStra: unqueued-sender-com-spec{data-element=CoOptmEl_stOptmElStra, can-invalidate=false, init-value=CoOptmEl_stOptmElStra_out}, provided-interface=IF_CoOptmEl_stOptmElStra
      P_CoOptmEl_stPrevElProdReq: unqueued-sender-com-spec{data-element=CoOptmEl_stPrevElProdReq, can-invalidate=false, init-value=CoOptmEl_stPrevElProdReq_out}, provided-interface=IF_CoOptmEl_stPrevElProdReq
      P_CoOptmEl_stSoCRefTyp: unqueued-sender-com-spec{data-element=CoOptmEl_stSoCRefTyp, can-invalidate=false, init-value=ConstantValue101}, provided-interface=IF_CoOptmEl_stSoCRefTyp
      P_CoOptmEl_stStraVoltBatt: unqueued-sender-com-spec{data-element=CoOptmEl_stStraVoltBatt, can-invalidate=false, init-value=CoOptmEl_stStraVoltBatt_out}, provided-interface=IF_CoOptmEl_stStraVoltBatt
      P_CoOptmEl_tiLdSoCAuthStop: unqueued-sender-com-spec{data-element=CoOptmEl_tiLdSoCAuthStop, can-invalidate=false, init-value=CoOptmEl_tiLdSoCAuthStop_out}, provided-interface=IF_CoOptmEl_tiLdSoCAuthStop
      P_CoOptmEl_uMinInc: unqueued-sender-com-spec{data-element=CoOptmEl_uMinInc, can-invalidate=false, init-value=CoOptmEl_uMinInc_out}, provided-interface=IF_CoOptmEl_uMinInc
      P_BatMgt_bBattAntiAgiAcvReq: unqueued-sender-com-spec{data-element=BatMgt_bBattAntiAgiAcvReq, can-invalidate=false, init-value=BatMgt_bBattAntiAgiAcvReq_out}, provided-interface=IF_BatMgt_bBattAntiAgiAcvReq
      P_BatMgt_bBattChProtAcvReq: unqueued-sender-com-spec{data-element=BatMgt_bBattChProtAcvReq, can-invalidate=false, init-value=BatMgt_bBattChProtAcvReq_out}, provided-interface=IF_BatMgt_bBattChProtAcvReq
      P_BatMgt_bBattSoCMinProtAcvReq: unqueued-sender-com-spec{data-element=BatMgt_bBattSoCMinProtAcvReq, can-invalidate=false, init-value=BatMgt_bBattSoCMinProtAcvReq_out}, provided-interface=IF_BatMgt_bBattSoCMinProtAcvReq
      P_BatMgt_bBattStopPrepAcvReq: unqueued-sender-com-spec{data-element=BatMgt_bBattStopPrepAcvReq, can-invalidate=false, init-value=BatMgt_bBattStopPrepAcvReq_out}, provided-interface=IF_BatMgt_bBattStopPrepAcvReq
      P_BatMgt_bBattTProtAcvReq: unqueued-sender-com-spec{data-element=BatMgt_bBattTProtAcvReq, can-invalidate=false, init-value=BatMgt_bBattTProtAcvReq_out}, provided-interface=IF_BatMgt_bBattTProtAcvReq
      P_BatMgt_ctStcAcvAntiAgiStra: unqueued-sender-com-spec{data-element=BatMgt_ctStcAcvAntiAgiStra, can-invalidate=false, init-value=BatMgt_ctStcAcvAntiAgiStra_out}, provided-interface=IF_BatMgt_ctStcAcvAntiAgiStra
      P_BatMgt_ctStcCnclAntiAgiStra: unqueued-sender-com-spec{data-element=BatMgt_ctStcCnclAntiAgiStra, can-invalidate=false, init-value=BatMgt_ctStcCnclAntiAgiStra_out}, provided-interface=IF_BatMgt_ctStcCnclAntiAgiStra
      P_BatMgt_grdNegSlopBattAntiAgi: unqueued-sender-com-spec{data-element=BatMgt_grdNegSlopBattAntiAgi, can-invalidate=false, init-value=BatMgt_grdNegSlopBattAntiAgi_out}, provided-interface=IF_BatMgt_grdNegSlopBattAntiAgi
      P_BatMgt_grdNegSlopBattTProt: unqueued-sender-com-spec{data-element=BatMgt_grdNegSlopBattTProt, can-invalidate=false, init-value=BatMgt_grdNegSlopBattTProt_out}, provided-interface=IF_BatMgt_grdNegSlopBattTProt
      P_BatMgt_grdPosSlopBattAntiAgi: unqueued-sender-com-spec{data-element=BatMgt_grdPosSlopBattAntiAgi, can-invalidate=false, init-value=BatMgt_grdPosSlopBattAntiAgi_out}, provided-interface=IF_BatMgt_grdPosSlopBattAntiAgi
      P_BatMgt_grdPosSlopBattTProt: unqueued-sender-com-spec{data-element=BatMgt_grdPosSlopBattTProt, can-invalidate=false, init-value=BatMgt_grdPosSlopBattTProt_out}, provided-interface=IF_BatMgt_grdPosSlopBattTProt
      P_BatMgt_rOfsSoC: unqueued-sender-com-spec{data-element=BatMgt_rOfsSoC, can-invalidate=false, init-value=BatMgt_rOfsSoC_out}, provided-interface=IF_BatMgt_rOfsSoC
      P_BatMgt_rStcSoCMax: unqueued-sender-com-spec{data-element=BatMgt_rStcSoCMax, can-invalidate=false, init-value=BatMgt_rStcSoCMax_out}, provided-interface=IF_BatMgt_rStcSoCMax
      P_BatMgt_rStcSoCMin: unqueued-sender-com-spec{data-element=BatMgt_rStcSoCMin, can-invalidate=false, init-value=BatMgt_rStcSoCMin_out}, provided-interface=IF_BatMgt_rStcSoCMin
      P_BatMgt_stBattSoH: unqueued-sender-com-spec{data-element=BatMgt_stBattSoH, can-invalidate=false, init-value=ConstantValue103}, provided-interface=IF_BatMgt_stBattSoH
      P_BatMgt_tiStcVoltBattDmg: unqueued-sender-com-spec{data-element=BatMgt_tiStcVoltBattDmg, can-invalidate=false, init-value=BatMgt_tiStcVoltBattDmg_out}, provided-interface=IF_BatMgt_tiStcVoltBattDmg
      P_BatMgt_uBattStrt: unqueued-sender-com-spec{data-element=BatMgt_uBattStrt, can-invalidate=false, init-value=BatMgt_uBattStrt_out}, provided-interface=IF_BatMgt_uBattStrt
      P_BatMgt_uReqEmMaxBattAntiAgi: unqueued-sender-com-spec{data-element=BatMgt_uReqEmMaxBattAntiAgi, can-invalidate=false, init-value=BatMgt_uReqEmMaxBattAntiAgi_out}, provided-interface=IF_BatMgt_uReqEmMaxBattAntiAgi
      P_BatMgt_uReqEmMaxBattTProt: unqueued-sender-com-spec{data-element=BatMgt_uReqEmMaxBattTProt, can-invalidate=false, init-value=BatMgt_uReqEmMaxBattTProt_out}, provided-interface=IF_BatMgt_uReqEmMaxBattTProt
      P_BatMgt_uReqEmMinBattAntiAgi: unqueued-sender-com-spec{data-element=BatMgt_uReqEmMinBattAntiAgi, can-invalidate=false, init-value=BatMgt_uReqEmMinBattAntiAgi_out}, provided-interface=IF_BatMgt_uReqEmMinBattAntiAgi
      P_BatMgt_uReqEmMinBattTProt: unqueued-sender-com-spec{data-element=BatMgt_uReqEmMinBattTProt, can-invalidate=false, init-value=BatMgt_uReqEmMinBattTProt_out}, provided-interface=IF_BatMgt_uReqEmMinBattTProt
      P_ElProdMgt_bAcvCoefFilDftAlt: unqueued-sender-com-spec{data-element=ElProdMgt_bAcvCoefFilDftAlt, can-invalidate=false, init-value=ElProdMgt_bAcvCoefFilDftAlt_out}, provided-interface=IF_ElProdMgt_bAcvCoefFilDftAlt
      P_ElProdMgt_iAltEstim: unqueued-sender-com-spec{data-element=ElProdMgt_iAltEstim, can-invalidate=false, init-value=ElProdMgt_iAltEstim_out}, provided-interface=IF_ElProdMgt_iAltEstim
      P_ElProdMgt_uBattSp: unqueued-sender-com-spec{data-element=ElProdMgt_uBattSp, can-invalidate=false, init-value=ElProdMgt_uBattSp_out}, provided-interface=IF_ElProdMgt_uBattSp
      P_BatMgt_uReqEmMinBattChProt: unqueued-sender-com-spec{data-element=BatMgt_uReqEmMinBattChProt, can-invalidate=false, init-value=BatMgt_uReqEmMinBattChProt_out}, provided-interface=IF_BatMgt_uReqEmMinBattChProt
      P_BatMgt_uReqEmMaxBattChProt: unqueued-sender-com-spec{data-element=BatMgt_uReqEmMaxBattChProt, can-invalidate=false, init-value=BatMgt_uReqEmMaxBattChProt_out}, provided-interface=IF_BatMgt_uReqEmMaxBattChProt
      P_BatMgt_grdPosSlopBattChProt: unqueued-sender-com-spec{data-element=BatMgt_grdPosSlopBattChProt, can-invalidate=false, init-value=BatMgt_grdPosSlopBattChProt_out}, provided-interface=IF_BatMgt_grdPosSlopBattChProt
      P_BatMgt_grdNegSlopBattChProt: unqueued-sender-com-spec{data-element=BatMgt_grdNegSlopBattChProt, can-invalidate=false, init-value=BatMgt_grdNegSlopBattChProt_out}, provided-interface=IF_BatMgt_grdNegSlopBattChProt
      P_CoOptmEl_iElNw: unqueued-sender-com-spec{data-element=CoOptmEl_iElNw, can-invalidate=false, init-value=CoOptmEl_iElNw_out}, provided-interface=IF_CoOptmEl_iElNw
      P_BatMgt_bAntiAgiStraEfcChIdc: unqueued-sender-com-spec{data-element=BatMgt_bAntiAgiStraEfcChIdc, can-invalidate=false, init-value=BatMgt_bAntiAgiStraEfcChIdc_out}, provided-interface=IF_BatMgt_bAntiAgiStraEfcChIdc
      P_BatMgt_bAntiAgiStraEndIdc: unqueued-sender-com-spec{data-element=BatMgt_bAntiAgiStraEndIdc, can-invalidate=false, init-value=BatMgt_bAntiAgiStraEndIdc_out}, provided-interface=IF_BatMgt_bAntiAgiStraEndIdc
      P_BatMgt_iBattMaxCkg: unqueued-sender-com-spec{data-element=BatMgt_iBattMaxCkg, can-invalidate=false, init-value=ConstantValue105}, provided-interface=IF_BatMgt_iBattMaxCkg
      P_BatMgt_resBattItNorm: unqueued-sender-com-spec{data-element=BatMgt_resBattItNorm, can-invalidate=false, init-value=BatMgt_resBattItNorm_out}, provided-interface=IF_BatMgt_resBattItNorm
      P_BatMgt_uBattMinCkg: unqueued-sender-com-spec{data-element=BatMgt_uBattMinCkg, can-invalidate=false, init-value=ConstantValue107}, provided-interface=IF_BatMgt_uBattMinCkg
      P_ElProdMgt_uOfsLossCor: unqueued-sender-com-spec{data-element=ElProdMgt_uOfsLossCor, can-invalidate=false, init-value=ElProdMgt_uOfsLossCor_out}, provided-interface=IF_ElProdMgt_uOfsLossCor
      P_CoOptmEl_iElProdMaxLdBatt: unqueued-sender-com-spec{data-element=CoOptmEl_iElProdMaxLdBatt, can-invalidate=false, init-value=CoOptmEl_iElProdMaxLdBatt_out}, provided-interface=IF_CoOptmEl_iElProdMaxLdBatt
      P_CoOptmEl_bAcvElCnsReq: unqueued-sender-com-spec{data-element=CoOptmEl_bAcvElCnsReq, can-invalidate=false, init-value=CoOptmEl_bAcvElCnsReq_out}, provided-interface=IF_CoOptmEl_bAcvElCnsReq
      P_CoOptmEl_stPrgChReq: unqueued-sender-com-spec{data-element=CoOptmEl_stPrgChReq, can-invalidate=false, init-value=CoOptmEl_stPrgChReq_out}, provided-interface=IF_CoOptmEl_stPrgChReq
    15 x require port:
      R_BatMgt__iBattMes: required-interface=DiagnosticMonitor
      R_BatMgt__resBattIt: required-interface=DiagnosticMonitor
      R_BatMgt__tBattMes: required-interface=DiagnosticMonitor
      R_BatMgt__uBattMes: required-interface=DiagnosticMonitor
      R_BatMgt__uBattRstrt: required-interface=DiagnosticMonitor
      R_ElProdMgt_CorLoss: required-interface=DiagnosticMonitor
      R_CoOptmEl_TqAlt: required-interface=DiagnosticMonitor
      R_BatMgt__uBattOc: required-interface=DiagnosticMonitor
      R_BatMgt__uBattStrt: required-interface=DiagnosticMonitor
      R_ElProdMgt_CorSpCur: required-interface=DiagnosticMonitor
      R_BatMgt__iBattMaxCkg: required-interface=DiagnosticMonitor
      R_BatMgt__rBattSoC: required-interface=DiagnosticMonitor
      R_BatMgt__uBattMinCkg: required-interface=DiagnosticMonitor
      R_UCE_stWkuMainRelSt: required-interface=IF_UCE_stWkuMainRelSt
      R_EcuM_CurrentMode: required-interface=EcuM_CurrentMode
    provide port P_ProdElEm_AftsNvramReset_1: server-com-spec{operation=op_ProdElEm_AftsNvramReset_1, queue-length=1}, provided-interface=IF_ProdElEm_AftsNvramReset_1
    provide port P_ProdElEm_AftsNvramWrite_1: server-com-spec{operation=op_CoEmSTT_AftsNvramWrite_1, queue-length=1}, provided-interface=IF_ProdElEm_AftsNvramWrite_1
    provide port P_ProdElEm_AftsNvramRead_1: server-com-spec{operation=op_ProdElEm_AftsNvramRead_1, queue-length=1}, provided-interface=IF_ProdElEm_AftsNvramRead_1
  219 x constant specification:
    Afts_bInhStSoCBatt_in
      value:
        boolean literal Afts_bInhStSoCBatt_in: type=DT_Afts_bInhStSoCBatt, value=false
    Afts_bLrnRstReq_rOfsSoC_in
      value:
        boolean literal Afts_bLrnRstReq_rOfsSoC_in: type=DT_Afts_bLrnRstReq_rOfsSoC, value=false
    Afts_bRstReq_stSoHBatt_in
      value:
        boolean literal Afts_bRstReq_stSoHBatt_in: type=DT_Afts_bRstReq_stSoHBatt, value=false
    Afts_bRstReqStcBatt_in
      value:
        boolean literal Afts_bRstReqStcBatt_in: type=DT_Afts_bRstReqStcBatt, value=false
    BatMgt_bAntiAgiStraEfcChIdc_out
      value:
        boolean literal BatMgt_bAntiAgiStraEfcChIdc_out: type=DT_BatMgt_bAntiAgiStraEfcChIdc, value=false
    BatMgt_bAntiAgiStraEndIdc_out
      value:
        boolean literal BatMgt_bAntiAgiStraEndIdc_out: type=DT_BatMgt_bAntiAgiStraEndIdc, value=false
    BatMgt_bBattAntiAgiAcvReq_in
      value:
        boolean literal BatMgt_bBattAntiAgiAcvReq_in: type=DT_BatMgt_bBattAntiAgiAcvReq, value=false
    BatMgt_bBattAntiAgiAcvReq_out
      value:
        boolean literal BatMgt_bBattAntiAgiAcvReq_out: type=DT_BatMgt_bBattAntiAgiAcvReq, value=false
    BatMgt_bBattChProtAcvReq_in
      value:
        boolean literal BatMgt_bBattChProtAcvReq_in: type=DT_BatMgt_bBattChProtAcvReq, value=false
    BatMgt_bBattChProtAcvReq_out
      value:
        boolean literal BatMgt_bBattChProtAcvReq_out: type=DT_BatMgt_bBattChProtAcvReq, value=false
    BatMgt_bBattSoCMinProtAcvReq_in
      value:
        boolean literal BatMgt_bBattSoCMinProtAcvReq_in: type=DT_BatMgt_bBattSoCMinProtAcvReq, value=false
    BatMgt_bBattSoCMinProtAcvReq_out
      value:
        boolean literal BatMgt_bBattSoCMinProtAcvReq_out: type=DT_BatMgt_bBattSoCMinProtAcvReq, value=false
    BatMgt_bBattStopPrepAcvReq_in
      value:
        boolean literal BatMgt_bBattStopPrepAcvReq_in: type=DT_BatMgt_bBattStopPrepAcvReq, value=false
    BatMgt_bBattStopPrepAcvReq_out
      value:
        boolean literal BatMgt_bBattStopPrepAcvReq_out: type=DT_BatMgt_bBattStopPrepAcvReq, value=false
    BatMgt_bBattTProtAcvReq_in
      value:
        boolean literal BatMgt_bBattTProtAcvReq_in: type=DT_BatMgt_bBattTProtAcvReq, value=true
    BatMgt_bBattTProtAcvReq_out
      value:
        boolean literal BatMgt_bBattTProtAcvReq_out: type=DT_BatMgt_bBattTProtAcvReq, value=true
    BatMgt_ctStcAcvAntiAgiStra_out
      value:
        integer literal BatMgt_ctStcAcvAntiAgiStra_out: type=DT_BatMgt_ctStcAcvAntiAgiStra, value=0
    BatMgt_ctStcCnclAntiAgiStra_out
      value:
        integer literal BatMgt_ctStcCnclAntiAgiStra_out: type=DT_BatMgt_ctStcCnclAntiAgiStra, value=0
    BatMgt_grdNegSlopBattAntiAgi_in
      value:
        integer literal BatMgt_grdNegSlopBattAntiAgi_in: type=DT_BatMgt_grdNegSlopBattAntiAgi, value=16
    BatMgt_grdNegSlopBattAntiAgi_out
      value:
        integer literal BatMgt_grdNegSlopBattAntiAgi_out: type=DT_BatMgt_grdNegSlopBattAntiAgi, value=16
    BatMgt_grdNegSlopBattChProt_in
      value:
        integer literal BatMgt_grdNegSlopBattChProt_in: type=DT_BatMgt_grdNegSlopBattChProt, value=16
    BatMgt_grdNegSlopBattChProt_out
      value:
        integer literal BatMgt_grdNegSlopBattChProt_out: type=DT_BatMgt_grdNegSlopBattChProt, value=16
    BatMgt_grdNegSlopBattTProt_in
      value:
        integer literal BatMgt_grdNegSlopBattTProt_in: type=DT_BatMgt_grdNegSlopBattTProt, value=16
    BatMgt_grdNegSlopBattTProt_out
      value:
        integer literal BatMgt_grdNegSlopBattTProt_out: type=DT_BatMgt_grdNegSlopBattTProt, value=16
    BatMgt_grdPosSlopBattAntiAgi_in
      value:
        integer literal BatMgt_grdPosSlopBattAntiAgi_in: type=DT_BatMgt_grdPosSlopBattAntiAgi, value=16
    BatMgt_grdPosSlopBattAntiAgi_out
      value:
        integer literal BatMgt_grdPosSlopBattAntiAgi_out: type=DT_BatMgt_grdPosSlopBattAntiAgi, value=16
    BatMgt_grdPosSlopBattChProt_in
      value:
        integer literal BatMgt_grdPosSlopBattChProt_in: type=DT_BatMgt_grdPosSlopBattChProt, value=1
    BatMgt_grdPosSlopBattChProt_out
      value:
        integer literal BatMgt_grdPosSlopBattChProt_out: type=DT_BatMgt_grdPosSlopBattChProt, value=1
    BatMgt_grdPosSlopBattTProt_in
      value:
        integer literal BatMgt_grdPosSlopBattTProt_in: type=DT_BatMgt_grdPosSlopBattTProt, value=16
    BatMgt_grdPosSlopBattTProt_out
      value:
        integer literal BatMgt_grdPosSlopBattTProt_out: type=DT_BatMgt_grdPosSlopBattTProt, value=16
    BatMgt_resBattItNorm_out
      value:
        integer literal BatMgt_resBattItNorm_out: type=DT_BatMgt_resBattItNorm, value=80
    BatMgt_rOfsSoC_in
      value:
        integer literal BatMgt_rOfsSoC_in: type=DT_BatMgt_rOfsSoC, value=0
    BatMgt_rOfsSoC_out
      value:
        integer literal BatMgt_rOfsSoC_out: type=DT_BatMgt_rOfsSoC, value=0
    BatMgt_rSoCErrEstim_in
      value:
        integer literal BatMgt_rSoCErrEstim_in: type=DT_BatMgt_rSoCErrEstim, value=0
    BatMgt_rSoCErrEstim_out
      value:
        integer literal BatMgt_rSoCErrEstim_out: type=DT_BatMgt_rSoCErrEstim, value=0
    BatMgt_rStcSoCMax_out
      value:
        integer literal BatMgt_rStcSoCMax_out: type=DT_BatMgt_rStcSoCMax, value=1120
    BatMgt_rStcSoCMin_out
      value:
        integer literal BatMgt_rStcSoCMin_out: type=DT_BatMgt_rStcSoCMin, value=1120
    BatMgt_stBattSt_out
      value:
        integer literal BatMgt_stBattSt_out: type=DT_BatMgt_stBattSt, value=3
    BatMgt_tiStcVoltBattDmg_out
      value:
        integer literal BatMgt_tiStcVoltBattDmg_out: type=DT_BatMgt_tiStcVoltBattDmg, value=0
    BatMgt_uBattStrt_out
      value:
        integer literal BatMgt_uBattStrt_out: type=DT_BatMgt_uBattStrt, value=1600
    BatMgt_uReqEmMaxBattAntiAgi_in
      value:
        integer literal BatMgt_uReqEmMaxBattAntiAgi_in: type=DT_BatMgt_uReqEmMaxBattAntiAgi, value=243
    BatMgt_uReqEmMaxBattAntiAgi_out
      value:
        integer literal BatMgt_uReqEmMaxBattAntiAgi_out: type=DT_BatMgt_uReqEmMaxBattAntiAgi, value=243
    BatMgt_uReqEmMaxBattChProt_in
      value:
        integer literal BatMgt_uReqEmMaxBattChProt_in: type=DT_BatMgt_uReqEmMaxBattChProt, value=170
    BatMgt_uReqEmMaxBattChProt_out
      value:
        integer literal BatMgt_uReqEmMaxBattChProt_out: type=DT_BatMgt_uReqEmMaxBattChProt, value=170
    BatMgt_uReqEmMaxBattTProt_in
      value:
        integer literal BatMgt_uReqEmMaxBattTProt_in: type=DT_BatMgt_uReqEmMaxBattTProt, value=243
    BatMgt_uReqEmMaxBattTProt_out
      value:
        integer literal BatMgt_uReqEmMaxBattTProt_out: type=DT_BatMgt_uReqEmMaxBattTProt, value=243
    BatMgt_uReqEmMinBattAntiAgi_in
      value:
        integer literal BatMgt_uReqEmMinBattAntiAgi_in: type=DT_BatMgt_uReqEmMinBattAntiAgi, value=195
    BatMgt_uReqEmMinBattAntiAgi_out
      value:
        integer literal BatMgt_uReqEmMinBattAntiAgi_out: type=DT_BatMgt_uReqEmMinBattAntiAgi, value=195
    BatMgt_uReqEmMinBattChProt_in
      value:
        integer literal BatMgt_uReqEmMinBattChProt_in: type=DT_BatMgt_uReqEmMinBattChProt, value=170
    BatMgt_uReqEmMinBattChProt_out
      value:
        integer literal BatMgt_uReqEmMinBattChProt_out: type=DT_BatMgt_uReqEmMinBattChProt, value=170
    BatMgt_uReqEmMinBattTProt_in
      value:
        integer literal BatMgt_uReqEmMinBattTProt_in: type=DT_BatMgt_uReqEmMinBattTProt, value=195
    BatMgt_uReqEmMinBattTProt_out
      value:
        integer literal BatMgt_uReqEmMinBattTProt_out: type=DT_BatMgt_uReqEmMinBattTProt, value=195
    ConstantValue
      value:
        integer literal ConstantValue: type=DT_BatMgt_iBattMes, value=0
    ConstantValue1
      value:
        integer literal ConstantValue1: type=DT_BatMgt_rBattSoCCor, value=0
    ConstantValue101
      value:
        integer literal ConstantValue101: type=DT_CoOptmEl_stSoCRefTyp, value=0
    ConstantValue103
      value:
        integer literal ConstantValue103: type=DT_BatMgt_stBattSoH, value=0
    ConstantValue105
      value:
        integer literal ConstantValue105: type=DT_BatMgt_iBattMaxCkg, value=-18
    ConstantValue107
      value:
        integer literal ConstantValue107: type=DT_BatMgt_uBattMinCkg, value=384
    ConstantValue11
      value:
        integer literal ConstantValue11: type=DT_CoEmSTT_rThdStopAuthSoCBatt, value=1120
    ConstantValue13
      value:
        boolean literal ConstantValue13: type=DT_ECU_bWkuMain, value=false
    ConstantValue15
      value:
        boolean literal ConstantValue15: type=DT_Ext_bNotAvl_rBattSoC, value=false
    ConstantValue17
      value:
        boolean literal ConstantValue17: type=DT_Ext_bNotAvl_tBattMes, value=false
    ConstantValue19
      value:
        boolean literal ConstantValue19: type=DT_Ext_bSTTCf, value=false
    ConstantValue21
      value:
        integer literal ConstantValue21: type=DT_Ext_spdVeh, value=0
    ConstantValue23
      value:
        integer literal ConstantValue23: type=DT_Ext_stElProdCf, value=0
    ConstantValue25
      value:
        integer literal ConstantValue25: type=DT_Ext_tCoMes, value=20
    ConstantValue27
      value:
        integer literal ConstantValue27: type=DT_TqLimUH_stDrivTyp, value=0
    ConstantValue29
      value:
        boolean literal ConstantValue29: type=DT_Ext_bNotAvl_iBattMes, value=false
    ConstantValue3
      value:
        integer literal ConstantValue3: type=DT_BatMgt_stBattSoC, value=0
    ConstantValue31
      value:
        boolean literal ConstantValue31: type=DT_Ext_bNotAvl_resBattIt, value=false
    ConstantValue33
      value:
        boolean literal ConstantValue33: type=DT_Ext_bNotAvl_uBattOc, value=false
    ConstantValue35
      value:
        integer literal ConstantValue35: type=DT_Ext_stBattTypCf, value=0
    ConstantValue37
      value:
        integer literal ConstantValue37: type=DT_Ext_uBattMes, value=1200
    ConstantValue39
      value:
        integer literal ConstantValue39: type=DT_AccP_rAccP, value=0
    ConstantValue41
      value:
        integer literal ConstantValue41: type=DT_BatMgt_stBattSoH, value=0
    ConstantValue43
      value:
        integer literal ConstantValue43: type=DT_CoEmCkg_stStrtRstrtFbCmd, value=0
    ConstantValue45
      value:
        boolean literal ConstantValue45: type=DT_CoEmSTT_bVSSAcvSt, value=false
    ConstantValue47
      value:
        integer literal ConstantValue47: type=DT_CoEmSTT_iElNwStop, value=40
    ConstantValue49
      value:
        integer literal ConstantValue49: type=DT_CoEmSTT_rThdStopAuthSoCCf1, value=1120
    ConstantValue5
      value:
        integer literal ConstantValue5: type=DT_BatMgt_tBattMes, value=0
    ConstantValue51
      value:
        integer literal ConstantValue51: type=DT_CoPt_noEgdGearCord, value=0
    ConstantValue53
      value:
        integer literal ConstantValue53: type=DT_CoPtSynt_stPwt, value=1
    ConstantValue55
      value:
        integer literal ConstantValue55: type=DT_CoPtUH_stTypSTTNotAvl, value=0
    ConstantValue57
      value:
        integer literal ConstantValue57: type=DT_Eng_nCkFil, value=0
    ConstantValue59
      value:
        integer literal ConstantValue59: type=DT_Ext_dstVehTotMes, value=0
    ConstantValue61
      value:
        integer literal ConstantValue61: type=DT_Ext_stVSSCf, value=0
    ConstantValue63
      value:
        integer literal ConstantValue63: type=DT_StopStrtEng_stCdnNxtCkg, value=0
    ConstantValue65
      value:
        integer literal ConstantValue65: type=DT_RvAltMgt_nRvAltMes, value=0
    ConstantValue67
      value:
        boolean literal ConstantValue67: type=DT_CoPtUH_bTestPrvtBltAcv, value=false
    ConstantValue69
      value:
        integer literal ConstantValue69: type=DT_CoStrtRStrt_stEngStrtReq, value=0
    ConstantValue7
      value:
        integer literal ConstantValue7: type=DT_BatMgt_uBattMes, value=640
    ConstantValue71
      value:
        integer literal ConstantValue71: type=DT_Ext_rAltCycOp, value=0
    ConstantValue73
      value:
        integer literal ConstantValue73: type=DT_Ext_tAir, value=20
    ConstantValue75
      value:
        integer literal ConstantValue75: type=DT_CoOptmEl_tqAlt, value=0
    ConstantValue77
      value:
        integer literal ConstantValue77: type=DT_BatMgt_rBattSoCCor, value=0
    ConstantValue79
      value:
        integer literal ConstantValue79: type=DT_BatMgt_resBattIt, value=0
    ConstantValue81
      value:
        integer literal ConstantValue81: type=DT_BatMgt_stBattSoC, value=0
    ConstantValue83
      value:
        integer literal ConstantValue83: type=DT_BatMgt_tBattMes, value=0
    ConstantValue85
      value:
        integer literal ConstantValue85: type=DT_BatMgt_uBattMes, value=640
    ConstantValue87
      value:
        integer literal ConstantValue87: type=DT_BatMgt_uBattOc, value=1408
    ConstantValue89
      value:
        integer literal ConstantValue89: type=DT_BatMgt_uBattRstrt, value=0
    ConstantValue9
      value:
        integer literal ConstantValue9: type=DT_CoEmSTT_rThdRstrtAuthSoCBatt, value=1120
    ConstantValue91
      value:
        integer literal ConstantValue91: type=DT_CoOptmEl_iElProd, value=0
    ConstantValue93
      value:
        integer literal ConstantValue93: type=DT_CoOptmEl_rOfsSoCSTT, value=0
    ConstantValue95
      value:
        integer literal ConstantValue95: type=DT_CoOptmEl_rThdRstrtAuthSoCCf1, value=0
    ConstantValue97
      value:
        integer literal ConstantValue97: type=DT_CoOptmEl_rThdStopAuthSoCCf2, value=0
    ConstantValue99
      value:
        integer literal ConstantValue99: type=DT_CoOptmEl_stElEProv, value=1
    CoOptmEl_bAcvElCnsReq_out
      value:
        boolean literal CoOptmEl_bAcvElCnsReq_out: type=DT_CoOptmEl_bAcvElCnsReq, value=false
    CoOptmEl_bAuthAntiAgiStra_in
      value:
        boolean literal CoOptmEl_bAuthAntiAgiStra_in: type=DT_CoOptmEl_bAuthAntiAgiStra, value=false
    CoOptmEl_bAuthAntiAgiStra_out
      value:
        boolean literal CoOptmEl_bAuthAntiAgiStra_out: type=DT_CoOptmEl_bAuthAntiAgiStra, value=false
    CoOptmEl_bfAcvConstEm1_out
      value:
        integer literal CoOptmEl_bfAcvConstEm1_out: type=DT_CoOptmEl_bfAcvConstEm1, value=0
    CoOptmEl_bfAcvConstEm2_out
      value:
        integer literal CoOptmEl_bfAcvConstEm2_out: type=DT_CoOptmEl_bfAcvConstEm2, value=0
    CoOptmEl_bWupAcv_out
      value:
        boolean literal CoOptmEl_bWupAcv_out: type=DT_CoOptmEl_bWupAcv, value=false
    CoOptmEl_grdNegSlop_in
      value:
        integer literal CoOptmEl_grdNegSlop_in: type=DT_CoOptmEl_grdNegSlop, value=16
    CoOptmEl_grdNegSlop_out
      value:
        integer literal CoOptmEl_grdNegSlop_out: type=DT_CoOptmEl_grdNegSlop, value=16
    CoOptmEl_grdPosSlop_in
      value:
        integer literal CoOptmEl_grdPosSlop_in: type=DT_CoOptmEl_grdPosSlop, value=16
    CoOptmEl_grdPosSlop_out
      value:
        integer literal CoOptmEl_grdPosSlop_out: type=DT_CoOptmEl_grdPosSlop, value=16
    CoOptmEl_iElNw_in
      value:
        integer literal CoOptmEl_iElNw_in: type=DT_CoOptmEl_iElNw, value=0
    CoOptmEl_iElNw_out
      value:
        integer literal CoOptmEl_iElNw_out: type=DT_CoOptmEl_iElNw, value=0
    CoOptmEl_iElProdMaxLdBatt_in
      value:
        integer literal CoOptmEl_iElProdMaxLdBatt_in: type=DT_CoOptmEl_iElProdMaxLdBatt, value=0
    CoOptmEl_iElProdMaxLdBatt_out
      value:
        integer literal CoOptmEl_iElProdMaxLdBatt_out: type=DT_CoOptmEl_iElProdMaxLdBatt, value=0
    CoOptmEl_rBattSoCSp_in
      value:
        integer literal CoOptmEl_rBattSoCSp_in: type=DT_CoOptmEl_rBattSoCSp, value=0
    CoOptmEl_rBattSoCSp_out
      value:
        integer literal CoOptmEl_rBattSoCSp_out: type=DT_CoOptmEl_rBattSoCSp, value=0
    CoOptmEl_rElRecup_out
      value:
        integer literal CoOptmEl_rElRecup_out: type=DT_CoOptmEl_rElRecup, value=50
    CoOptmEl_rElRest_out
      value:
        integer literal CoOptmEl_rElRest_out: type=DT_CoOptmEl_rElRest, value=50
    CoOptmEl_stDetConstNegSlop_out
      value:
        integer literal CoOptmEl_stDetConstNegSlop_out: type=DT_CoOptmEl_stDetConstNegSlop, value=0
    CoOptmEl_stDetConstPosSlop_out
      value:
        integer literal CoOptmEl_stDetConstPosSlop_out: type=DT_CoOptmEl_stDetConstPosSlop, value=0
    CoOptmEl_stDetConstVoltMax_out
      value:
        integer literal CoOptmEl_stDetConstVoltMax_out: type=DT_CoOptmEl_stDetConstVoltMax, value=0
    CoOptmEl_stDetConstVoltMin_out
      value:
        integer literal CoOptmEl_stDetConstVoltMin_out: type=DT_CoOptmEl_stDetConstVoltMin, value=0
    CoOptmEl_stElLvlProd_out
      value:
        integer literal CoOptmEl_stElLvlProd_out: type=DT_CoOptmEl_stElLvlProd, value=0
    CoOptmEl_stElProd_out
      value:
        integer literal CoOptmEl_stElProd_out: type=DT_CoOptmEl_stElProd, value=0
    CoOptmEl_stOptmElCf_in
      value:
        integer literal CoOptmEl_stOptmElCf_in: type=DT_CoOptmEl_stOptmElCf, value=0
    CoOptmEl_stOptmElCf_out
      value:
        integer literal CoOptmEl_stOptmElCf_out: type=DT_CoOptmEl_stOptmElCf, value=0
    CoOptmEl_stOptmElStra_in
      value:
        integer literal CoOptmEl_stOptmElStra_in: type=DT_CoOptmEl_stOptmElStra, value=0
    CoOptmEl_stOptmElStra_out
      value:
        integer literal CoOptmEl_stOptmElStra_out: type=DT_CoOptmEl_stOptmElStra, value=0
    CoOptmEl_stPrevElProdReq_in
      value:
        integer literal CoOptmEl_stPrevElProdReq_in: type=DT_CoOptmEl_stPrevElProdReq, value=0
    CoOptmEl_stPrevElProdReq_out
      value:
        integer literal CoOptmEl_stPrevElProdReq_out: type=DT_CoOptmEl_stPrevElProdReq, value=0
    CoOptmEl_stPrgChReq_in
      value:
        integer literal CoOptmEl_stPrgChReq_in: type=DT_CoOptmEl_stPrgChReq, value=0
    CoOptmEl_stPrgChReq_out
      value:
        integer literal CoOptmEl_stPrgChReq_out: type=DT_CoOptmEl_stPrgChReq, value=0
    CoOptmEl_stStraVoltBatt_in
      value:
        integer literal CoOptmEl_stStraVoltBatt_in: type=DT_CoOptmEl_stStraVoltBatt, value=0
    CoOptmEl_stStraVoltBatt_out
      value:
        integer literal CoOptmEl_stStraVoltBatt_out: type=DT_CoOptmEl_stStraVoltBatt, value=0
    CoOptmEl_tiLdSoCAuthStop_in
      value:
        integer literal CoOptmEl_tiLdSoCAuthStop_in: type=DT_CoOptmEl_tiLdSoCAuthStop, value=0
    CoOptmEl_tiLdSoCAuthStop_out
      value:
        integer literal CoOptmEl_tiLdSoCAuthStop_out: type=DT_CoOptmEl_tiLdSoCAuthStop, value=0
    CoOptmEl_uMax_in
      value:
        integer literal CoOptmEl_uMax_in: type=DT_CoOptmEl_uMax, value=1357
    CoOptmEl_uMax_out
      value:
        integer literal CoOptmEl_uMax_out: type=DT_CoOptmEl_uMax, value=1357
    CoOptmEl_uMin_out
      value:
        integer literal CoOptmEl_uMin_out: type=DT_CoOptmEl_uMin, value=1562
    CoOptmEl_uMinInc_in
      value:
        integer literal CoOptmEl_uMinInc_in: type=DT_CoOptmEl_uMinInc, value=1357
    CoOptmEl_uMinInc_out
      value:
        integer literal CoOptmEl_uMinInc_out: type=DT_CoOptmEl_uMinInc, value=1357
    CoStrtRStrt_stAcvReq_in
      value:
        integer literal CoStrtRStrt_stAcvReq_in: type=DT_CoStrtRStrt_stAcvReq, value=0
    ElecMgt_stPrioVoltMax_in
      value:
        integer literal ElecMgt_stPrioVoltMax_in: type=DT_ElecMgt_stPrioVoltMax, value=2
    ElecMgt_stPrioVoltMin_in
      value:
        integer literal ElecMgt_stPrioVoltMin_in: type=DT_ElecMgt_stPrioVoltMin, value=2
    ElecMgt_uReqProdMax_in
      value:
        integer literal ElecMgt_uReqProdMax_in: type=DT_ElecMgt_uReqProdMax, value=170
    ElecMgt_uReqProdMin_in
      value:
        integer literal ElecMgt_uReqProdMin_in: type=DT_ElecMgt_uReqProdMin, value=170
    ElecMgt_uReqProdSlope_in
      value:
        integer literal ElecMgt_uReqProdSlope_in: type=DT_ElecMgt_uReqProdSlope, value=1
    ElProdMgt_bAcvCoefFilDftAlt_in
      value:
        boolean literal ElProdMgt_bAcvCoefFilDftAlt_in: type=DT_ElProdMgt_bAcvCoefFilDftAlt, value=false
    ElProdMgt_bAcvCoefFilDftAlt_out
      value:
        boolean literal ElProdMgt_bAcvCoefFilDftAlt_out: type=DT_ElProdMgt_bAcvCoefFilDftAlt, value=false
    ElProdMgt_iAltEstim_in
      value:
        integer literal ElProdMgt_iAltEstim_in: type=DT_ElProdMgt_iAltEstim, value=0
    ElProdMgt_iAltEstim_out
      value:
        integer literal ElProdMgt_iAltEstim_out: type=DT_ElProdMgt_iAltEstim, value=0
    ElProdMgt_iExctMax_out
      value:
        integer literal ElProdMgt_iExctMax_out: type=DT_ElProdMgt_iExctMax, value=0
    ElProdMgt_rSoCErrEstim_in
      value:
        integer literal ElProdMgt_rSoCErrEstim_in: type=DT_ElProdMgt_rSoCErrEstim, value=0
    ElProdMgt_rSoCErrEstim_out
      value:
        integer literal ElProdMgt_rSoCErrEstim_out: type=DT_ElProdMgt_rSoCErrEstim, value=0
    ElProdMgt_stProdPrgCh_out
      value:
        integer literal ElProdMgt_stProdPrgCh_out: type=DT_ElProdMgt_stProdPrgCh, value=7
    ElProdMgt_stProdPrgChDi_nEng_out
      value:
        integer literal ElProdMgt_stProdPrgChDi_nEng_out: type=DT_ElProdMgt_stProdPrgChDi_nEng, value=4
    ElProdMgt_tqAltEstim_in
      value:
        integer literal ElProdMgt_tqAltEstim_in: type=DT_ElProdMgt_tqAltEstim, value=0
    ElProdMgt_tqAltEstim_out
      value:
        integer literal ElProdMgt_tqAltEstim_out: type=DT_ElProdMgt_tqAltEstim, value=0
    ElProdMgt_uBattSp_in
      value:
        integer literal ElProdMgt_uBattSp_in: type=DT_ElProdMgt_uBattSp, value=1357
    ElProdMgt_uBattSp_out
      value:
        integer literal ElProdMgt_uBattSp_out: type=DT_ElProdMgt_uBattSp, value=1357
    ElProdMgt_uElProdSp_in
      value:
        integer literal ElProdMgt_uElProdSp_in: type=DT_ElProdMgt_uElProdSp, value=1357
    ElProdMgt_uElProdSp_out
      value:
        integer literal ElProdMgt_uElProdSp_out: type=DT_ElProdMgt_uElProdSp, value=1357
    ElProdMgt_uOfs_uElProdSp_in
      value:
        integer literal ElProdMgt_uOfs_uElProdSp_in: type=DT_ElProdMgt_uOfs_uElProdSp, value=0
    ElProdMgt_uOfs_uElProdSp_out
      value:
        integer literal ElProdMgt_uOfs_uElProdSp_out: type=DT_ElProdMgt_uOfs_uElProdSp, value=0
    ElProdMgt_uOfsLossCor_in
      value:
        integer literal ElProdMgt_uOfsLossCor_in: type=DT_ElProdMgt_uOfsLossCor, value=0
    ElProdMgt_uOfsLossCor_out
      value:
        integer literal ElProdMgt_uOfsLossCor_out: type=DT_ElProdMgt_uOfsLossCor, value=0
    Ext_bArchiCf_in
      value:
        boolean literal Ext_bArchiCf_in: type=DT_Ext_bArchiCf, value=false
    Ext_bAuthWupElMgt_in
      value:
        boolean literal Ext_bAuthWupElMgt_in: type=DT_Ext_bAuthWupElMgt, value=false
    Ext_bfAcvConstElMgt1_in
      value:
        integer literal Ext_bfAcvConstElMgt1_in: type=DT_Ext_bfAcvConstElMgt1, value=0
    Ext_bfAcvConstElMgt2_in
      value:
        integer literal Ext_bfAcvConstElMgt2_in: type=DT_Ext_bfAcvConstElMgt2, value=0
    Ext_bfAcvConstElMgt3_in
      value:
        integer literal Ext_bfAcvConstElMgt3_in: type=DT_Ext_bfAcvConstElMgt3, value=0
    Ext_bfAcvConstEng1_in
      value:
        integer literal Ext_bfAcvConstEng1_in: type=DT_Ext_bfAcvConstEng1, value=0
    Ext_bfAcvConstReTra1_in
      value:
        integer literal Ext_bfAcvConstReTra1_in: type=DT_Ext_bfAcvConstReTra1, value=0
    Ext_bNotAvl_rBattSoCLoResl_in
      value:
        boolean literal Ext_bNotAvl_rBattSoCLoResl_in: type=DT_Ext_bNotAvl_rBattSoCLoResl, value=false
    Ext_bNotAvl_uBattClc_in
      value:
        boolean literal Ext_bNotAvl_uBattClc_in: type=DT_Ext_bNotAvl_uBattClc, value=false
    Ext_bNotAvl_uBattRstrt_in
      value:
        boolean literal Ext_bNotAvl_uBattRstrt_in: type=DT_Ext_bNotAvl_uBattRstrt, value=false
    Ext_bNotAvl_uBattStrt_in
      value:
        boolean literal Ext_bNotAvl_uBattStrt_in: type=DT_Ext_bNotAvl_uBattStrt, value=false
    Ext_ctDay_in
      value:
        integer literal Ext_ctDay_in: type=DT_Ext_ctDay, value=0
    Ext_ctSec_in
      value:
        integer literal Ext_ctSec_in: type=DT_Ext_ctSec, value=0
    Ext_ctYr_in
      value:
        integer literal Ext_ctYr_in: type=DT_Ext_ctYr, value=0
    Ext_facRatTqAltCf_in
      value:
        integer literal Ext_facRatTqAltCf_in: type=DT_Ext_facRatTqAltCf, value=0
    Ext_iAltExct_in
      value:
        integer literal Ext_iAltExct_in: type=DT_Ext_iAltExct, value=0
    Ext_iBattMaxCkg_in
      value:
        integer literal Ext_iBattMaxCkg_in: type=DT_Ext_iBattMaxCkg, value=-18
    Ext_iBattMes_in
      value:
        integer literal Ext_iBattMes_in: type=DT_Ext_iBattMes, value=0
    Ext_idxCtlAltProvIdf_in
      value:
        integer literal Ext_idxCtlAltProvIdf_in: type=DT_Ext_idxCtlAltProvIdf, value=7
    Ext_rBattSoC_in
      value:
        integer literal Ext_rBattSoC_in: type=DT_Ext_rBattSoC, value=1120
    Ext_rBattSoCLoResl_in
      value:
        integer literal Ext_rBattSoCLoResl_in: type=DT_Ext_rBattSoCLoResl, value=0
    Ext_rCorSoCHyb_in
      value:
        integer literal Ext_rCorSoCHyb_in: type=DT_Ext_rCorSoCHyb, value=0
    Ext_resBattIt_in
      value:
        integer literal Ext_resBattIt_in: type=DT_Ext_resBattIt, value=640
    Ext_resBattItNorm_in
      value:
        integer literal Ext_resBattItNorm_in: type=DT_Ext_resBattItNorm, value=0
    Ext_stAltClasCf_in
      value:
        integer literal Ext_stAltClasCf_in: type=DT_Ext_stAltClasCf, value=0
    Ext_stBattSoC_in
      value:
        integer literal Ext_stBattSoC_in: type=DT_Ext_stBattSoC, value=3
    Ext_tBattMes_in
      value:
        integer literal Ext_tBattMes_in: type=DT_Ext_tBattMes, value=-60
    Ext_uBattClc_in
      value:
        integer literal Ext_uBattClc_in: type=DT_Ext_uBattClc, value=1536
    Ext_uBattMinCkg_in
      value:
        integer literal Ext_uBattMinCkg_in: type=DT_Ext_uBattMinCkg, value=384
    Ext_uBattOc_in
      value:
        integer literal Ext_uBattOc_in: type=DT_Ext_uBattOc, value=1600
    Ext_uBattRstrt_in
      value:
        integer literal Ext_uBattRstrt_in: type=DT_Ext_uBattRstrt, value=0
    Ext_uBattStrt_in
      value:
        integer literal Ext_uBattStrt_in: type=DT_Ext_uBattStrt, value=0
    MCT_tqFrntMchEstim_in
      value:
        integer literal MCT_tqFrntMchEstim_in: type=DT_MCT_tqFrntMchEstim, value=0
    RvAltMgt_bIdcVldCurGenMod_in
      value:
        boolean literal RvAltMgt_bIdcVldCurGenMod_in: type=DT_RvAltMgt_bIdcVldCurGenMod, value=true
    RvAltMgt_iRvAltGenModEstim_in
      value:
        integer literal RvAltMgt_iRvAltGenModEstim_in: type=DT_RvAltMgt_iRvAltGenModEstim, value=0
    RvAltMgt_stRvAltModReq_in
      value:
        integer literal RvAltMgt_stRvAltModReq_in: type=DT_RvAltMgt_stRvAltModReq, value=0
    RvAltMgt_tqRvAltGenModEstim_in
      value:
        integer literal RvAltMgt_tqRvAltGenModEstim_in: type=DT_RvAltMgt_tqRvAltGenModEstim, value=0
    RvAltMgt_tRvAltECUMes_in
      value:
        integer literal RvAltMgt_tRvAltECUMes_in: type=DT_RvAltMgt_tRvAltECUMes, value=-1
    RvAltMgt_uRvAltMes_in
      value:
        integer literal RvAltMgt_uRvAltMes_in: type=DT_RvAltMgt_uRvAltMes, value=170
    TqDem_bTqGrdLim_in
      value:
        boolean literal TqDem_bTqGrdLim_in: type=DT_TqDem_bTqGrdLim, value=false
    TqLimUH_bfAcvConstFrntTra1_in
      value:
        integer literal TqLimUH_bfAcvConstFrntTra1_in: type=DT_TqLimUH_bfAcvConstFrntTra1, value=0
    TqLimUH_bFrzReqTqVoltCtl_in
      value:
        boolean literal TqLimUH_bFrzReqTqVoltCtl_in: type=DT_TqLimUH_bFrzReqTqVoltCtl, value=false
    TqLimUH_grdLimVoltCtlDynMax_in
      value:
        integer literal TqLimUH_grdLimVoltCtlDynMax_in: type=DT_TqLimUH_grdLimVoltCtlDynMax, value=4
    TqLimUH_stReqBlsVoltCtl_in
      value:
        integer literal TqLimUH_stReqBlsVoltCtl_in: type=DT_TqLimUH_stReqBlsVoltCtl, value=0
    TqLimUH_stReqUnBlsVoltCtl_in
      value:
        integer literal TqLimUH_stReqUnBlsVoltCtl_in: type=DT_TqLimUH_stReqUnBlsVoltCtl, value=0
    VSSCtzMgt_bAcvElCnsReq_in
      value:
        boolean literal VSSCtzMgt_bAcvElCnsReq_in: type=DT_VSSCtzMgt_bAcvElCnsReq, value=false
  internal behavior IB_ProdElEm: component=PRODELEM
    operation invoked event EV_ProdElEm_AftsNvramReset_1: start-on-event=RE_ProdElEm_AftsNvramReset_1, operation=P_ProdElEm_AftsNvramReset_1.op_ProdElEm_AftsNvramReset_1
    operation invoked event EV_ProdElEm_AftsNvramRead_1: start-on-event=RE_ProdElEm_AftsNvramRead_1, operation=P_ProdElEm_AftsNvramRead_1.op_ProdElEm_AftsNvramRead_1
    mode switch event EV_ProdElEm_005_MSE: start-on-event=RE_ProdElEm_005_MSE, activation=ENTRY, mode=R_EcuM_CurrentMode.currentMode.RUN
    timing event EV_ProdElEm_004_TEV: mode-dependency=dependent-on-mode=[R_UCE_stWkuMainRelSt.RCD_stWkuMainRelSt.PreMainWakeUp, R_UCE_stWkuMainRelSt.RCD_stWkuMainRelSt.PostMainWakeUp, R_UCE_stWkuMainRelSt.RCD_stWkuMainRelSt.Invalid], start-on-event=RE_ProdElEm_004_TEV, period=0.01
    mode switch event EV_ProdElEm_001_MSE: start-on-event=RE_ProdElEm_001_MSE, activation=ENTRY, mode=R_EcuM_CurrentMode.currentMode.RUN
    mode switch event EV_ProdElEm_003_MSE: start-on-event=RE_ProdElEm_003_MSE, activation=ENTRY, mode=R_EcuM_CurrentMode.currentMode.RUN
    operation invoked event EV_ProdElEm_AftsNvramWrite_1: start-on-event=RE_ProdElEm_AftsNvramWrite_1, operation=P_ProdElEm_AftsNvramWrite_1.op_CoEmSTT_AftsNvramWrite_1
    timing event EV_ProdElEm_006_TEV: mode-dependency=dependent-on-mode=[R_UCE_stWkuMainRelSt.RCD_stWkuMainRelSt.PreMainWakeUp, R_UCE_stWkuMainRelSt.RCD_stWkuMainRelSt.PostMainWakeUp, R_UCE_stWkuMainRelSt.RCD_stWkuMainRelSt.Invalid], start-on-event=RE_ProdElEm_006_TEV, period=0.01
    timing event EV_ProdElEm_002_TEV: mode-dependency=dependent-on-mode=R_UCE_stWkuMainRelSt.RCD_stWkuMainRelSt.Invalid, start-on-event=RE_ProdElEm_002_TEV, period=0.01
    9 x runnable:
      RE_ProdElEm_AftsNvramRead_1
      RE_ProdElEm_004_TEV
        48 x data receive point:
          dr_Ext_bNotAvl_uBattOc: data-element=R_Ext_bNotAvl_uBattOc.Ext_bNotAvl_uBattOc
          dr_Ext_stBattSoC: data-element=R_Ext_stBattSoC.Ext_stBattSoC
          dr_Ext_bNotAvl_rBattSoCLoResl: data-element=R_Ext_bNotAvl_rBattSoCLoResl.Ext_bNotAvl_rBattSoCLoResl
          dr_Ext_resBattItNorm: data-element=R_Ext_resBattItNorm.Ext_resBattItNorm
          dr_Ext_rBattSoC: data-element=R_Ext_rBattSoC.Ext_rBattSoC
          dr_RvAltMgt_uRvAltMes: data-element=R_RvAltMgt_uRvAltMes.RvAltMgt_uRvAltMes
          dr_Ext_iBattMaxCkg: data-element=R_Ext_iBattMaxCkg.Ext_iBattMaxCkg
          dr_CoOptmEl_stOptmElCf: data-element=R_CoOptmEl_stOptmElCf.CoOptmEl_stOptmElCf
          dr_CoEmSTT_rThdStopAuthSoCBatt: data-element=R_CoEmSTT_rThdStopAuthSoCBatt.CoEmSTT_rThdStopAuthSoCBatt
          dr_Ext_bNotAvl_uBattStrt: data-element=R_Ext_bNotAvl_uBattStrt.Ext_bNotAvl_uBattStrt
          dr_Ext_stBattTypCf: data-element=R_Ext_stBattTypCf.Ext_stBattTypCf
          dr_Ext_tCoMes: data-element=R_Ext_tCoMes.Ext_tCoMes
          dr_Ext_bNotAvl_uBattClc: data-element=R_Ext_bNotAvl_uBattClc.Ext_bNotAvl_uBattClc
          dr_Ext_ctSec: data-element=R_Ext_ctSec.Ext_ctSec
          dr_Afts_bInhStSoCBatt: data-element=R_Afts_bInhStSoCBatt.Afts_bInhStSoCBatt
          dr_CoOptmEl_uMax: data-element=R_CoOptmEl_uMax.CoOptmEl_uMax
          dr_Afts_bLrnRstReq_rOfsSoC: data-element=R_Afts_bLrnRstReq_rOfsSoC.Afts_bLrnRstReq_rOfsSoC
          dr_CoOptmEl_tiLdSoCAuthStop: data-element=R_CoOptmEl_tiLdSoCAuthStop.CoOptmEl_tiLdSoCAuthStop
          dr_CoOptmEl_stOptmElStra: data-element=R_CoOptmEl_stOptmElStra.CoOptmEl_stOptmElStra
          dr_Ext_uBattMes: data-element=R_Ext_uBattMes.Ext_uBattMes
          dr_Ext_ctYr: data-element=R_Ext_ctYr.Ext_ctYr
          dr_Ext_bNotAvl_iBattMes: data-element=R_Ext_bNotAvl_iBattMes.Ext_bNotAvl_iBattMes
          dr_Ext_resBattIt: data-element=R_Ext_resBattIt.Ext_resBattIt
          dr_Ext_bNotAvl_tBattMes: data-element=R_Ext_bNotAvl_tBattMes.Ext_bNotAvl_tBattMes
          dr_CoOptmEl_stPrevElProdReq: data-element=R_CoOptmEl_stPrevElProdReq.CoOptmEl_stPrevElProdReq
          dr_CoOptmEl_bAuthAntiAgiStra: data-element=R_CoOptmEl_bAuthAntiAgiStra.CoOptmEl_bAuthAntiAgiStra
          dr_Ext_rBattSoCLoResl: data-element=R_Ext_rBattSoCLoResl.Ext_rBattSoCLoResl
          dr_ElProdMgt_uOfs_uElProdSp: data-element=R_ElProdMgt_uOfs_uElProdSp.ElProdMgt_uOfs_uElProdSp
          dr_Ext_uBattStrt: data-element=R_Ext_uBattStrt.Ext_uBattStrt
          dr_Ext_bNotAvl_rBattSoC: data-element=R_Ext_bNotAvl_rBattSoC.Ext_bNotAvl_rBattSoC
          dr_Ext_bNotAvl_resBattIt: data-element=R_Ext_bNotAvl_resBattIt.Ext_bNotAvl_resBattIt
          dr_CoOptmEl_iElProdMaxLdBatt: data-element=R_CoOptmEl_iElProdMaxLdBatt.CoOptmEl_iElProdMaxLdBatt
          dr_Ext_iBattMes: data-element=R_Ext_iBattMes.Ext_iBattMes
          dr_ElProdMgt_uBattSp: data-element=R_ElProdMgt_uBattSp.ElProdMgt_uBattSp
          dr_Ext_tBattMes: data-element=R_Ext_tBattMes.Ext_tBattMes
          dr_CoOptmEl_stStraVoltBatt: data-element=R_CoOptmEl_stStraVoltBatt.CoOptmEl_stStraVoltBatt
          dr_Ext_uBattRstrt: data-element=R_Ext_uBattRstrt.Ext_uBattRstrt
          dr_CoPtSynt_stPwt: data-element=R_CoPtSynt_stPwt.CoPtSynt_stPwt
          dr_Ext_uBattOc: data-element=R_Ext_uBattOc.Ext_uBattOc
          dr_Afts_bRstReq_stSoHBatt: data-element=R_Afts_bRstReq_stSoHBatt.Afts_bRstReq_stSoHBatt
          dr_Ext_uBattClc: data-element=R_Ext_uBattClc.Ext_uBattClc
          dr_Ext_bNotAvl_uBattRstrt: data-element=R_Ext_bNotAvl_uBattRstrt.Ext_bNotAvl_uBattRstrt
          dr_Ext_stElProdCf: data-element=R_Ext_stElProdCf.Ext_stElProdCf
          dr_ElProdMgt_rSoCErrEstim: data-element=R_ElProdMgt_rSoCErrEstim.ElProdMgt_rSoCErrEstim
          dr_Ext_dstVehTotMes: data-element=R_Ext_dstVehTotMes.Ext_dstVehTotMes
          dr_Ext_ctDay: data-element=R_Ext_ctDay.Ext_ctDay
          dr_Afts_bRstReqStcBatt: data-element=R_Afts_bRstReqStcBatt.Afts_bRstReqStcBatt
          dr_Ext_uBattMinCkg: data-element=R_Ext_uBattMinCkg.Ext_uBattMinCkg
        40 x data send point:
          ds_BatMgt_iBattMaxCkg: data-element=P_BatMgt_iBattMaxCkg.BatMgt_iBattMaxCkg
          ds_BatMgt_rStcSoCMin: data-element=P_BatMgt_rStcSoCMin.BatMgt_rStcSoCMin
          ds_BatMgt_rStcSoCMax: data-element=P_BatMgt_rStcSoCMax.BatMgt_rStcSoCMax
          ds_BatMgt_uBattMes: data-element=P_BatMgt_uBattMes.BatMgt_uBattMes
          ds_BatMgt_rBattSoCCor: data-element=P_BatMgt_rBattSoCCor.BatMgt_rBattSoCCor
          ds_BatMgt_grdNegSlopBattChProt: data-element=P_BatMgt_grdNegSlopBattChProt.BatMgt_grdNegSlopBattChProt
          ds_BatMgt_uReqEmMinBattChProt: data-element=P_BatMgt_uReqEmMinBattChProt.BatMgt_uReqEmMinBattChProt
          ds_BatMgt_uReqEmMinBattTProt: data-element=P_BatMgt_uReqEmMinBattTProt.BatMgt_uReqEmMinBattTProt
          ds_BatMgt_resBattItNorm: data-element=P_BatMgt_resBattItNorm.BatMgt_resBattItNorm
          ds_BatMgt_stBattSt: data-element=P_BatMgt_stBattSt.BatMgt_stBattSt
          ds_BatMgt_grdNegSlopBattAntiAgi: data-element=P_BatMgt_grdNegSlopBattAntiAgi.BatMgt_grdNegSlopBattAntiAgi
          ds_BatMgt_bBattAntiAgiAcvReq: data-element=P_BatMgt_bBattAntiAgiAcvReq.BatMgt_bBattAntiAgiAcvReq
          ds_BatMgt_iBattMes: data-element=P_BatMgt_iBattMes.BatMgt_iBattMes
          ds_BatMgt_bAntiAgiStraEndIdc: data-element=P_BatMgt_bAntiAgiStraEndIdc.BatMgt_bAntiAgiStraEndIdc
          ds_BatMgt_grdPosSlopBattTProt: data-element=P_BatMgt_grdPosSlopBattTProt.BatMgt_grdPosSlopBattTProt
          ds_BatMgt_bBattStopPrepAcvReq: data-element=P_BatMgt_bBattStopPrepAcvReq.BatMgt_bBattStopPrepAcvReq
          ds_BatMgt_stBattSoC: data-element=P_BatMgt_stBattSoC.BatMgt_stBattSoC
          ds_BatMgt_uBattRstrt: data-element=P_BatMgt_uBattRstrt.BatMgt_uBattRstrt
          ds_BatMgt_ctStcAcvAntiAgiStra: data-element=P_BatMgt_ctStcAcvAntiAgiStra.BatMgt_ctStcAcvAntiAgiStra
          ds_BatMgt_rOfsSoC: data-element=P_BatMgt_rOfsSoC.BatMgt_rOfsSoC
          ds_BatMgt_bBattSoCMinProtAcvReq: data-element=P_BatMgt_bBattSoCMinProtAcvReq.BatMgt_bBattSoCMinProtAcvReq
          ds_BatMgt_bBattChProtAcvReq: data-element=P_BatMgt_bBattChProtAcvReq.BatMgt_bBattChProtAcvReq
          ds_BatMgt_bAntiAgiStraEfcChIdc: data-element=P_BatMgt_bAntiAgiStraEfcChIdc.BatMgt_bAntiAgiStraEfcChIdc
          ds_BatMgt_uBattOc: data-element=P_BatMgt_uBattOc.BatMgt_uBattOc
          ds_BatMgt_uReqEmMaxBattChProt: data-element=P_BatMgt_uReqEmMaxBattChProt.BatMgt_uReqEmMaxBattChProt
          ds_BatMgt_stBattSoH: data-element=P_BatMgt_stBattSoH.BatMgt_stBattSoH
          ds_BatMgt_uReqEmMaxBattTProt: data-element=P_BatMgt_uReqEmMaxBattTProt.BatMgt_uReqEmMaxBattTProt
          ds_BatMgt_uBattStrt: data-element=P_BatMgt_uBattStrt.BatMgt_uBattStrt
          ds_BatMgt_uBattMinCkg: data-element=P_BatMgt_uBattMinCkg.BatMgt_uBattMinCkg
          ds_BatMgt_grdPosSlopBattAntiAgi: data-element=P_BatMgt_grdPosSlopBattAntiAgi.BatMgt_grdPosSlopBattAntiAgi
          ds_BatMgt_grdNegSlopBattTProt: data-element=P_BatMgt_grdNegSlopBattTProt.BatMgt_grdNegSlopBattTProt
          ds_BatMgt_bBattTProtAcvReq: data-element=P_BatMgt_bBattTProtAcvReq.BatMgt_bBattTProtAcvReq
          ds_BatMgt_uReqEmMaxBattAntiAgi: data-element=P_BatMgt_uReqEmMaxBattAntiAgi.BatMgt_uReqEmMaxBattAntiAgi
          ds_BatMgt_tBattMes: data-element=P_BatMgt_tBattMes.BatMgt_tBattMes
          ds_BatMgt_ctStcCnclAntiAgiStra: data-element=P_BatMgt_ctStcCnclAntiAgiStra.BatMgt_ctStcCnclAntiAgiStra
          ds_BatMgt_resBattIt: data-element=P_BatMgt_resBattIt.BatMgt_resBattIt
          ds_BatMgt_uReqEmMinBattAntiAgi: data-element=P_BatMgt_uReqEmMinBattAntiAgi.BatMgt_uReqEmMinBattAntiAgi
          ds_BatMgt_rSoCErrEstim: data-element=P_BatMgt_rSoCErrEstim.BatMgt_rSoCErrEstim
          ds_BatMgt_grdPosSlopBattChProt: data-element=P_BatMgt_grdPosSlopBattChProt.BatMgt_grdPosSlopBattChProt
          ds_BatMgt_tiStcVoltBattDmg: data-element=P_BatMgt_tiStcVoltBattDmg.BatMgt_tiStcVoltBattDmg
        26 x sync call:
          ssp_BatMgt__iBattMes: operation=R_BatMgt__iBattMes.SetEventStatus
          ssp_FRM_bInhBatMgt_uBattRstrt: operation=R_FRM_bInhBatMgt_uBattRstrt.GetFunctionPermission
          ssp_FRM_bInhBatMgtVoltBattClc: operation=R_FRM_bInhBatMgtVoltBattClc.GetFunctionPermission
          ssp_FRM_bInhBatMgtTBattMes: operation=R_FRM_bInhBatMgtTBattMes.GetFunctionPermission
          ssp_BatMgt__uBattMinCkg: operation=R_BatMgt__uBattMinCkg.SetEventStatus
          ssp_FRM_bAcvBatMgtDftValStBatt: operation=R_FRM_bAcvBatMgtDftValStBatt.GetFunctionPermission
          ssp_BatMgt__tBattMes: operation=R_BatMgt__tBattMes.SetEventStatus
          ssp_BatMgt__uBattRstrt: operation=R_BatMgt__uBattRstrt.SetEventStatus
          ssp_BatMgt__uBattMes: operation=R_BatMgt__uBattMes.SetEventStatus
          ssp_FRM_bInhBatMgtOfsSoC: operation=R_FRM_bInhBatMgtOfsSoC.GetFunctionPermission
          ssp_FRM_bInhBatMgtSoCClc: operation=R_FRM_bInhBatMgtSoCClc.GetFunctionPermission
          ssp_FRM_bInhBatMgtSoH: operation=R_FRM_bInhBatMgtSoH.GetFunctionPermission
          ssp_FRM_bInhBatMgtCurBattMes: operation=R_FRM_bInhBatMgtCurBattMes.GetFunctionPermission
          ssp_FRM_bInhBatMgtTiAntiAgi: operation=R_FRM_bInhBatMgtTiAntiAgi.GetFunctionPermission
          ssp_FRM_bInhBatMgtBattNotConn: operation=R_FRM_bInhBatMgtBattNotConn.GetFunctionPermission
          ssp_BatMgt__iBattMaxCkg: operation=R_BatMgt__iBattMaxCkg.SetEventStatus
          ssp_BatMgt__uBattOc: operation=R_BatMgt__uBattOc.SetEventStatus
          ssp_BatMgt__resBattIt: operation=R_BatMgt__resBattIt.SetEventStatus
          ssp_BatMgt__uBattStrt: operation=R_BatMgt__uBattStrt.SetEventStatus
          ssp_FRM_bInhBatMgtTestCohVolt: operation=R_FRM_bInhBatMgtTestCohVolt.GetFunctionPermission
          ssp_FRM_bInhBatMgtStcBattSoC: operation=R_FRM_bInhBatMgtStcBattSoC.GetFunctionPermission
          ssp_FRM_bInhBatMgtPerAntiAgi: operation=R_FRM_bInhBatMgtPerAntiAgi.GetFunctionPermission
          ssp_FRM_bInhBatMgtDiagSoC: operation=R_FRM_bInhBatMgtDiagSoC.GetFunctionPermission
          ssp_FRM_bInhBatMgtStSoCAfts: operation=R_FRM_bInhBatMgtStSoCAfts.GetFunctionPermission
          ssp_BatMgt__rBattSoC: operation=R_BatMgt__rBattSoC.SetEventStatus
          ssp_FRM_bInhBatMgtKmAntiAgi: operation=R_FRM_bInhBatMgtKmAntiAgi.GetFunctionPermission
      RE_ProdElEm_AftsNvramWrite_1
      RE_ProdElEm_002_TEV
        84 x data receive point:
          dr_ElecMgt_uReqProdMax: data-element=R_ElecMgt_uReqProdMax.ElecMgt_uReqProdMax
          dr_ECU_bWkuMain: data-element=R_ECU_bWkuMain.ECU_bWkuMain
          dr_Ext_bNotAvl_uBattClc: data-element=R_Ext_bNotAvl_uBattClc.Ext_bNotAvl_uBattClc
          dr_Ext_bfAcvConstEng1: data-element=R_Ext_bfAcvConstEng1.Ext_bfAcvConstEng1
          dr_Ext_bNotAvl_iBattMes: data-element=R_Ext_bNotAvl_iBattMes.Ext_bNotAvl_iBattMes
          dr_CoEmSTT_bVSSAcvSt: data-element=R_CoEmSTT_bVSSAcvSt.CoEmSTT_bVSSAcvSt
          dr_Eng_nCkFil: data-element=R_Eng_nCkFil.Eng_nCkFil
          dr_CoEmSTT_rThdStopAuthSoCCf1: data-element=R_CoEmSTT_rThdStopAuthSoCCf1.CoEmSTT_rThdStopAuthSoCCf1
          dr_BatMgt_uReqEmMaxBattChProt: data-element=R_BatMgt_uReqEmMaxBattChProt.BatMgt_uReqEmMaxBattChProt
          dr_BatMgt_rBattSoCCor: data-element=R_BatMgt_rBattSoCCor.BatMgt_rBattSoCCor
          dr_Ext_bAuthWupElMgt: data-element=R_Ext_bAuthWupElMgt.Ext_bAuthWupElMgt
          dr_Ext_tCoMes: data-element=R_Ext_tCoMes.Ext_tCoMes
          dr_BatMgt_bBattChProtAcvReq: data-element=R_BatMgt_bBattChProtAcvReq.BatMgt_bBattChProtAcvReq
          dr_BatMgt_grdPosSlopBattAntiAgi: data-element=R_BatMgt_grdPosSlopBattAntiAgi.BatMgt_grdPosSlopBattAntiAgi
          dr_BatMgt_uReqEmMinBattAntiAgi: data-element=R_BatMgt_uReqEmMinBattAntiAgi.BatMgt_uReqEmMinBattAntiAgi
          dr_BatMgt_bBattAntiAgiAcvReq: data-element=R_BatMgt_bBattAntiAgiAcvReq.BatMgt_bBattAntiAgiAcvReq
          dr_RvAltMgt_tqRvAltGenModEstim: data-element=R_RvAltMgt_tqRvAltGenModEstim.RvAltMgt_tqRvAltGenModEstim
          dr_CoEmSTT_iElNwStop: data-element=R_CoEmSTT_iElNwStop.CoEmSTT_iElNwStop
          dr_ElecMgt_stPrioVoltMax: data-element=R_ElecMgt_stPrioVoltMax.ElecMgt_stPrioVoltMax
          dr_StopStrtEng_stCdnNxtCkg: data-element=R_StopStrtEng_stCdnNxtCkg.StopStrtEng_stCdnNxtCkg
          dr_RvAltMgt_iRvAltGenModEstim: data-element=R_RvAltMgt_iRvAltGenModEstim.RvAltMgt_iRvAltGenModEstim
          dr_Ext_bNotAvl_tBattMes: data-element=R_Ext_bNotAvl_tBattMes.Ext_bNotAvl_tBattMes
          dr_ElecMgt_uReqProdMin: data-element=R_ElecMgt_uReqProdMin.ElecMgt_uReqProdMin
          dr_Ext_bfAcvConstElMgt1: data-element=R_Ext_bfAcvConstElMgt1.Ext_bfAcvConstElMgt1
          dr_BatMgt_grdPosSlopBattTProt: data-element=R_BatMgt_grdPosSlopBattTProt.BatMgt_grdPosSlopBattTProt
          dr_ElProdMgt_bAcvCoefFilDftAlt: data-element=R_ElProdMgt_bAcvCoefFilDftAlt.ElProdMgt_bAcvCoefFilDftAlt
          dr_BatMgt_uReqEmMaxBattTProt: data-element=R_BatMgt_uReqEmMaxBattTProt.BatMgt_uReqEmMaxBattTProt
          dr_Ext_dstVehTotMes: data-element=R_Ext_dstVehTotMes.Ext_dstVehTotMes
          dr_BatMgt_grdNegSlopBattChProt: data-element=R_BatMgt_grdNegSlopBattChProt.BatMgt_grdNegSlopBattChProt
          dr_CoEmSTT_rThdRstrtAuthSoCBatt: data-element=R_CoEmSTT_rThdRstrtAuthSoCBatt.CoEmSTT_rThdRstrtAuthSoCBatt
          dr_Ext_rCorSoCHyb: data-element=R_Ext_rCorSoCHyb.Ext_rCorSoCHyb
          dr_ElProdMgt_uOfsLossCor: data-element=R_ElProdMgt_uOfsLossCor.ElProdMgt_uOfsLossCor
          dr_CoStrtRStrt_stEngStrtReq: data-element=R_CoStrtRStrt_stEngStrtReq.CoStrtRStrt_stEngStrtReq
          dr_Ext_bfAcvConstElMgt2: data-element=R_Ext_bfAcvConstElMgt2.Ext_bfAcvConstElMgt2
          dr_BatMgt_uReqEmMaxBattAntiAgi: data-element=R_BatMgt_uReqEmMaxBattAntiAgi.BatMgt_uReqEmMaxBattAntiAgi
          dr_TqLimUH_stDrivTyp: data-element=R_TqLimUH_stDrivTyp.TqLimUH_stDrivTyp
          dr_Ext_tAir: data-element=R_Ext_tAir.Ext_tAir
          dr_Ext_bSTTCf: data-element=R_Ext_bSTTCf.Ext_bSTTCf
          dr_BatMgt_bBattTProtAcvReq: data-element=R_BatMgt_bBattTProtAcvReq.BatMgt_bBattTProtAcvReq
          dr_CoPt_noEgdGearCord: data-element=R_CoPt_noEgdGearCord.CoPt_noEgdGearCord
          dr_TqLimUH_bFrzReqTqVoltCtl: data-element=R_TqLimUH_bFrzReqTqVoltCtl.TqLimUH_bFrzReqTqVoltCtl
          dr_BatMgt_grdNegSlopBattTProt: data-element=R_BatMgt_grdNegSlopBattTProt.BatMgt_grdNegSlopBattTProt
          dr_Ext_bfAcvConstReTra1: data-element=R_Ext_bfAcvConstReTra1.Ext_bfAcvConstReTra1
          dr_BatMgt_tBattMes: data-element=R_BatMgt_tBattMes.BatMgt_tBattMes
          dr_TqLimUH_bfAcvConstFrntTra1: data-element=R_TqLimUH_bfAcvConstFrntTra1.TqLimUH_bfAcvConstFrntTra1
          dr_RvAltMgt_tRvAltECUMes: data-element=R_RvAltMgt_tRvAltECUMes.RvAltMgt_tRvAltECUMes
          dr_BatMgt_uReqEmMinBattChProt: data-element=R_BatMgt_uReqEmMinBattChProt.BatMgt_uReqEmMinBattChProt
          dr_VSSCtzMgt_bAcvElCnsReq: data-element=R_VSSCtzMgt_bAcvElCnsReq.VSSCtzMgt_bAcvElCnsReq
          dr_Ext_stAltClasCf: data-element=R_Ext_stAltClasCf.Ext_stAltClasCf
          dr_TqDem_bTqGrdLim: data-element=R_TqDem_bTqGrdLim.TqDem_bTqGrdLim
          dr_BatMgt_uBattMes: data-element=R_BatMgt_uBattMes.BatMgt_uBattMes
          dr_ElProdMgt_tqAltEstim: data-element=R_ElProdMgt_tqAltEstim.ElProdMgt_tqAltEstim
          dr_ElecMgt_uReqProdSlope: data-element=R_ElecMgt_uReqProdSlope.ElecMgt_uReqProdSlope
          dr_Ext_bArchiCf: data-element=R_Ext_bArchiCf.Ext_bArchiCf
          dr_CoEmCkg_stStrtRstrtFbCmd: data-element=R_CoEmCkg_stStrtRstrtFbCmd.CoEmCkg_stStrtRstrtFbCmd
          dr_Ext_bNotAvl_rBattSoC: data-element=R_Ext_bNotAvl_rBattSoC.Ext_bNotAvl_rBattSoC
          dr_BatMgt_grdNegSlopBattAntiAgi: data-element=R_BatMgt_grdNegSlopBattAntiAgi.BatMgt_grdNegSlopBattAntiAgi
          dr_Ext_stVSSCf: data-element=R_Ext_stVSSCf.Ext_stVSSCf
          dr_RvAltMgt_stRvAltModReq: data-element=R_RvAltMgt_stRvAltModReq.RvAltMgt_stRvAltModReq
          dr_BatMgt_uReqEmMinBattTProt: data-element=R_BatMgt_uReqEmMinBattTProt.BatMgt_uReqEmMinBattTProt
          dr_TqLimUH_stReqBlsVoltCtl: data-element=R_TqLimUH_stReqBlsVoltCtl.TqLimUH_stReqBlsVoltCtl
          dr_ElProdMgt_uOfs_uElProdSp: data-element=R_ElProdMgt_uOfs_uElProdSp.ElProdMgt_uOfs_uElProdSp
          dr_Ext_spdVeh: data-element=R_Ext_spdVeh.Ext_spdVeh
          dr_BatMgt_iBattMes: data-element=R_BatMgt_iBattMes.BatMgt_iBattMes
          dr_Ext_stElProdCf: data-element=R_Ext_stElProdCf.Ext_stElProdCf
          dr_BatMgt_grdPosSlopBattChProt: data-element=R_BatMgt_grdPosSlopBattChProt.BatMgt_grdPosSlopBattChProt
          dr_MCT_tqFrntMchEstim: data-element=R_MCT_tqFrntMchEstim.MCT_tqFrntMchEstim
          dr_BatMgt_bBattSoCMinProtAcvReq: data-element=R_BatMgt_bBattSoCMinProtAcvReq.BatMgt_bBattSoCMinProtAcvReq
          dr_BatMgt_rSoCErrEstim: data-element=R_BatMgt_rSoCErrEstim.BatMgt_rSoCErrEstim
          dr_ElProdMgt_iAltEstim: data-element=R_ElProdMgt_iAltEstim.ElProdMgt_iAltEstim
          dr_BatMgt_stBattSoC: data-element=R_BatMgt_stBattSoC.BatMgt_stBattSoC
          dr_ElProdMgt_uElProdSp: data-element=R_ElProdMgt_uElProdSp.ElProdMgt_uElProdSp
          dr_CoPtUH_bTestPrvtBltAcv: data-element=R_CoPtUH_bTestPrvtBltAcv.CoPtUH_bTestPrvtBltAcv
          dr_AccP_rAccP: data-element=R_AccP_rAccP.AccP_rAccP
          dr_Ext_rAltCycOp: data-element=R_Ext_rAltCycOp.Ext_rAltCycOp
          dr_CoStrtRStrt_stAcvReq: data-element=R_CoStrtRStrt_stAcvReq.CoStrtRStrt_stAcvReq
          dr_TqLimUH_stReqUnBlsVoltCtl: data-element=R_TqLimUH_stReqUnBlsVoltCtl.TqLimUH_stReqUnBlsVoltCtl
          dr_ElecMgt_stPrioVoltMin: data-element=R_ElecMgt_stPrioVoltMin.ElecMgt_stPrioVoltMin
          dr_BatMgt_stBattSoH: data-element=R_BatMgt_stBattSoH.BatMgt_stBattSoH
          dr_Ext_bfAcvConstElMgt3: data-element=R_Ext_bfAcvConstElMgt3.Ext_bfAcvConstElMgt3
          dr_BatMgt_rOfsSoC: data-element=R_BatMgt_rOfsSoC.BatMgt_rOfsSoC
          dr_CoPtUH_stTypSTTNotAvl: data-element=R_CoPtUH_stTypSTTNotAvl.CoPtUH_stTypSTTNotAvl
          dr_CoPtSynt_stPwt: data-element=R_CoPtSynt_stPwt.CoPtSynt_stPwt
          dr_BatMgt_bBattStopPrepAcvReq: data-element=R_BatMgt_bBattStopPrepAcvReq.BatMgt_bBattStopPrepAcvReq
        34 x data send point:
          ds_CoOptmEl_iElNw: data-element=P_CoOptmEl_iElNw.CoOptmEl_iElNw
          ds_CoOptmEl_iElProdMaxLdBatt: data-element=P_CoOptmEl_iElProdMaxLdBatt.CoOptmEl_iElProdMaxLdBatt
          ds_CoOptmEl_stPrevElProdReq: data-element=P_CoOptmEl_stPrevElProdReq.CoOptmEl_stPrevElProdReq
          ds_CoOptmEl_tiLdSoCAuthStop: data-element=P_CoOptmEl_tiLdSoCAuthStop.CoOptmEl_tiLdSoCAuthStop
          ds_CoOptmEl_bAuthAntiAgiStra: data-element=P_CoOptmEl_bAuthAntiAgiStra.CoOptmEl_bAuthAntiAgiStra
          ds_CoOptmEl_stDetConstPosSlop: data-element=P_CoOptmEl_stDetConstPosSlop.CoOptmEl_stDetConstPosSlop
          ds_CoOptmEl_stSoCRefTyp: data-element=P_CoOptmEl_stSoCRefTyp.CoOptmEl_stSoCRefTyp
          ds_CoOptmEl_rBattSoCSp: data-element=P_CoOptmEl_rBattSoCSp.CoOptmEl_rBattSoCSp
          ds_CoOptmEl_bWupAcv: data-element=P_CoOptmEl_bWupAcv.CoOptmEl_bWupAcv
          ds_CoOptmEl_stStraVoltBatt: data-element=P_CoOptmEl_stStraVoltBatt.CoOptmEl_stStraVoltBatt
          ds_CoOptmEl_rElRest: data-element=P_CoOptmEl_rElRest.CoOptmEl_rElRest
          ds_CoOptmEl_bfAcvConstEm1: data-element=P_CoOptmEl_bfAcvConstEm1.CoOptmEl_bfAcvConstEm1
          ds_CoOptmEl_stDetConstNegSlop: data-element=P_CoOptmEl_stDetConstNegSlop.CoOptmEl_stDetConstNegSlop
          ds_CoOptmEl_stDetConstVoltMin: data-element=P_CoOptmEl_stDetConstVoltMin.CoOptmEl_stDetConstVoltMin
          ds_CoOptmEl_rElRecup: data-element=P_CoOptmEl_rElRecup.CoOptmEl_rElRecup
          ds_CoOptmEl_stOptmElCf: data-element=P_CoOptmEl_stOptmElCf.CoOptmEl_stOptmElCf
          ds_CoOptmEl_stDetConstVoltMax: data-element=P_CoOptmEl_stDetConstVoltMax.CoOptmEl_stDetConstVoltMax
          ds_CoOptmEl_stElEProv: data-element=P_CoOptmEl_stElEProv.CoOptmEl_stElEProv
          ds_CoOptmEl_stOptmElStra: data-element=P_CoOptmEl_stOptmElStra.CoOptmEl_stOptmElStra
          ds_CoOptmEl_bfAcvConstEm2: data-element=P_CoOptmEl_bfAcvConstEm2.CoOptmEl_bfAcvConstEm2
          ds_CoOptmEl_uMax: data-element=P_CoOptmEl_uMax.CoOptmEl_uMax
          ds_CoOptmEl_stElLvlProd: data-element=P_CoOptmEl_stElLvlProd.CoOptmEl_stElLvlProd
          ds_CoOptmEl_stPrgChReq: data-element=P_CoOptmEl_stPrgChReq.CoOptmEl_stPrgChReq
          ds_CoOptmEl_rThdRstrtAuthSoCCf1: data-element=P_CoOptmEl_rThdRstrtAuthSoCCf1.CoOptmEl_rThdRstrtAuthSoCCf1
          ds_CoOptmEl_uMinInc: data-element=P_CoOptmEl_uMinInc.CoOptmEl_uMinInc
          ds_CoOptmEl_tqAlt: data-element=P_CoOptmEl_tqAlt.CoOptmEl_tqAlt
          ds_CoOptmEl_rThdStopAuthSoCCf2: data-element=P_CoOptmEl_rThdStopAuthSoCCf2.CoOptmEl_rThdStopAuthSoCCf2
          ds_CoOptmEl_grdPosSlop: data-element=P_CoOptmEl_grdPosSlop.CoOptmEl_grdPosSlop
          ds_CoOptmEl_uMin: data-element=P_CoOptmEl_uMin.CoOptmEl_uMin
          ds_CoOptmEl_iElProd: data-element=P_CoOptmEl_iElProd.CoOptmEl_iElProd
          ds_CoOptmEl_bAcvElCnsReq: data-element=P_CoOptmEl_bAcvElCnsReq.CoOptmEl_bAcvElCnsReq
          ds_CoOptmEl_grdNegSlop: data-element=P_CoOptmEl_grdNegSlop.CoOptmEl_grdNegSlop
          ds_CoOptmEl_rOfsSoCSTT: data-element=P_CoOptmEl_rOfsSoCSTT.CoOptmEl_rOfsSoCSTT
          ds_CoOptmEl_stElProd: data-element=P_CoOptmEl_stElProd.CoOptmEl_stElProd
        29 x sync call:
          ssp_FRM_bInhCoOptmElFrzLvlProd: operation=R_FRM_bInhCoOptmElFrzLvlProd.GetFunctionPermission
          ssp_FRM_bAcvCoOptmElMinSoCReq: operation=R_FRM_bAcvCoOptmElMinSoCReq.GetFunctionPermission
          ssp_FRM_bInhCoOptmElTHom_iBatt: operation=R_FRM_bInhCoOptmElTHom_iBatt.GetFunctionPermission
          ssp_CoOptmEl_TqAlt: operation=R_CoOptmEl_TqAlt.SetEventStatus
          ssp_FRM_bAcvCoOptmElSatLvlProd: operation=R_FRM_bAcvCoOptmElSatLvlProd.GetFunctionPermission
          ssp_FRM_bAcvCoOptmElDftLvlProd: operation=R_FRM_bAcvCoOptmElDftLvlProd.GetFunctionPermission
          ssp_FRM_bAcvCoOptmElProdElEProv: operation=R_FRM_bAcvCoOptmElProdElEProv.GetFunctionPermission
          ssp_FRM_bInhCoOptmElCurAuxEstim: operation=R_FRM_bInhCoOptmElCurAuxEstim.GetFunctionPermission
          ssp_FRM_bInhCoOptmElRvAltLoss: operation=R_FRM_bInhCoOptmElRvAltLoss.GetFunctionPermission
          ssp_FRM_bInhCoOptmElTHom_tAirExt: operation=R_FRM_bInhCoOptmElTHom_tAirExt.GetFunctionPermission
          ssp_FRM_bInhCoOptmElTHom_tBatt: operation=R_FRM_bInhCoOptmElTHom_tBatt.GetFunctionPermission
          ssp_FRM_bInhCoOptmElReTraReq: operation=R_FRM_bInhCoOptmElReTraReq.GetFunctionPermission
          ssp_FRM_bInhCoOptmElTHom_spdVeh: operation=R_FRM_bInhCoOptmElTHom_spdVeh.GetFunctionPermission
          ssp_FRM_bInhCoOptmElElMgtReq: operation=R_FRM_bInhCoOptmElElMgtReq.GetFunctionPermission
          ssp_FRM_bInhCoOptmElWup_tBatt: operation=R_FRM_bInhCoOptmElWup_tBatt.GetFunctionPermission
          ssp_FRM_bInhCoOptmElFrntTraReq: operation=R_FRM_bInhCoOptmElFrntTraReq.GetFunctionPermission
          ssp_FRM_bInhCoOptmElWupElMgt: operation=R_FRM_bInhCoOptmElWupElMgt.GetFunctionPermission
          ssp_FRM_bInhCoOptmElStra_tAirExt: operation=R_FRM_bInhCoOptmElStra_tAirExt.GetFunctionPermission
          ssp_FRM_bAcvCoOptmElSoCSpDftVal: operation=R_FRM_bAcvCoOptmElSoCSpDftVal.GetFunctionPermission
          ssp_FRM_bAcvCoOptmElSlopStra: operation=R_FRM_bAcvCoOptmElSlopStra.GetFunctionPermission
          ssp_FRM_bInhCoOptmElElMgtOldReq: operation=R_FRM_bInhCoOptmElElMgtOldReq.GetFunctionPermission
          ssp_FRM_bAcvCoOptmEl_tBatt: operation=R_FRM_bAcvCoOptmEl_tBatt.GetFunctionPermission
          ssp_FRM_bAcvCoOptmElDftSoC: operation=R_FRM_bAcvCoOptmElDftSoC.GetFunctionPermission
          ssp_FRM_bInhCoOptmElTHomElMgt: operation=R_FRM_bInhCoOptmElTHomElMgt.GetFunctionPermission
          ssp_FRM_bAcvCoOptmEl_tCo: operation=R_FRM_bAcvCoOptmEl_tCo.GetFunctionPermission
          ssp_FRM_bInhCoOptmElEngReq: operation=R_FRM_bInhCoOptmElEngReq.GetFunctionPermission
          ssp_FRM_bAcvCoOptmElBattElEProv: operation=R_FRM_bAcvCoOptmElBattElEProv.GetFunctionPermission
          ssp_FRM_bInhCoOptmElBlsProd: operation=R_FRM_bInhCoOptmElBlsProd.GetFunctionPermission
          ssp_FRM_bInhCoOptmElBackUpStra: operation=R_FRM_bInhCoOptmElBackUpStra.GetFunctionPermission
      RE_ProdElEm_AftsNvramReset_1
      RE_ProdElEm_001_MSE
        34 x data send point:
          ds_CoOptmEl_stPrgChReq: data-element=P_CoOptmEl_stPrgChReq.CoOptmEl_stPrgChReq
          ds_CoOptmEl_rThdStopAuthSoCCf2: data-element=P_CoOptmEl_rThdStopAuthSoCCf2.CoOptmEl_rThdStopAuthSoCCf2
          ds_CoOptmEl_uMin: data-element=P_CoOptmEl_uMin.CoOptmEl_uMin
          ds_CoOptmEl_stSoCRefTyp: data-element=P_CoOptmEl_stSoCRefTyp.CoOptmEl_stSoCRefTyp
          ds_CoOptmEl_bWupAcv: data-element=P_CoOptmEl_bWupAcv.CoOptmEl_bWupAcv
          ds_CoOptmEl_stElLvlProd: data-element=P_CoOptmEl_stElLvlProd.CoOptmEl_stElLvlProd
          ds_CoOptmEl_stPrevElProdReq: data-element=P_CoOptmEl_stPrevElProdReq.CoOptmEl_stPrevElProdReq
          ds_CoOptmEl_bfAcvConstEm1: data-element=P_CoOptmEl_bfAcvConstEm1.CoOptmEl_bfAcvConstEm1
          ds_CoOptmEl_uMinInc: data-element=P_CoOptmEl_uMinInc.CoOptmEl_uMinInc
          ds_CoOptmEl_stStraVoltBatt: data-element=P_CoOptmEl_stStraVoltBatt.CoOptmEl_stStraVoltBatt
          ds_CoOptmEl_iElProd: data-element=P_CoOptmEl_iElProd.CoOptmEl_iElProd
          ds_CoOptmEl_tiLdSoCAuthStop: data-element=P_CoOptmEl_tiLdSoCAuthStop.CoOptmEl_tiLdSoCAuthStop
          ds_CoOptmEl_stElProd: data-element=P_CoOptmEl_stElProd.CoOptmEl_stElProd
          ds_CoOptmEl_stDetConstVoltMax: data-element=P_CoOptmEl_stDetConstVoltMax.CoOptmEl_stDetConstVoltMax
          ds_CoOptmEl_stDetConstVoltMin: data-element=P_CoOptmEl_stDetConstVoltMin.CoOptmEl_stDetConstVoltMin
          ds_CoOptmEl_bAuthAntiAgiStra: data-element=P_CoOptmEl_bAuthAntiAgiStra.CoOptmEl_bAuthAntiAgiStra
          ds_CoOptmEl_iElNw: data-element=P_CoOptmEl_iElNw.CoOptmEl_iElNw
          ds_CoOptmEl_uMax: data-element=P_CoOptmEl_uMax.CoOptmEl_uMax
          ds_CoOptmEl_stOptmElCf: data-element=P_CoOptmEl_stOptmElCf.CoOptmEl_stOptmElCf
          ds_CoOptmEl_stElEProv: data-element=P_CoOptmEl_stElEProv.CoOptmEl_stElEProv
          ds_CoOptmEl_rThdRstrtAuthSoCCf1: data-element=P_CoOptmEl_rThdRstrtAuthSoCCf1.CoOptmEl_rThdRstrtAuthSoCCf1
          ds_CoOptmEl_rBattSoCSp: data-element=P_CoOptmEl_rBattSoCSp.CoOptmEl_rBattSoCSp
          ds_CoOptmEl_stDetConstPosSlop: data-element=P_CoOptmEl_stDetConstPosSlop.CoOptmEl_stDetConstPosSlop
          ds_CoOptmEl_stOptmElStra: data-element=P_CoOptmEl_stOptmElStra.CoOptmEl_stOptmElStra
          ds_CoOptmEl_rElRecup: data-element=P_CoOptmEl_rElRecup.CoOptmEl_rElRecup
          ds_CoOptmEl_bAcvElCnsReq: data-element=P_CoOptmEl_bAcvElCnsReq.CoOptmEl_bAcvElCnsReq
          ds_CoOptmEl_rOfsSoCSTT: data-element=P_CoOptmEl_rOfsSoCSTT.CoOptmEl_rOfsSoCSTT
          ds_CoOptmEl_bfAcvConstEm2: data-element=P_CoOptmEl_bfAcvConstEm2.CoOptmEl_bfAcvConstEm2
          ds_CoOptmEl_grdNegSlop: data-element=P_CoOptmEl_grdNegSlop.CoOptmEl_grdNegSlop
          ds_CoOptmEl_iElProdMaxLdBatt: data-element=P_CoOptmEl_iElProdMaxLdBatt.CoOptmEl_iElProdMaxLdBatt
          ds_CoOptmEl_grdPosSlop: data-element=P_CoOptmEl_grdPosSlop.CoOptmEl_grdPosSlop
          ds_CoOptmEl_rElRest: data-element=P_CoOptmEl_rElRest.CoOptmEl_rElRest
          ds_CoOptmEl_stDetConstNegSlop: data-element=P_CoOptmEl_stDetConstNegSlop.CoOptmEl_stDetConstNegSlop
          ds_CoOptmEl_tqAlt: data-element=P_CoOptmEl_tqAlt.CoOptmEl_tqAlt
      RE_ProdElEm_006_TEV
        28 x data receive point:
          dr_CoOptmEl_iElNw: data-element=R_CoOptmEl_iElNw.CoOptmEl_iElNw
          dr_Eng_nCkFil: data-element=R_Eng_nCkFil.Eng_nCkFil
          dr_CoOptmEl_stPrgChReq: data-element=R_CoOptmEl_stPrgChReq.CoOptmEl_stPrgChReq
          dr_BatMgt_rBattSoCCor: data-element=R_BatMgt_rBattSoCCor.BatMgt_rBattSoCCor
          dr_Ext_tAir: data-element=R_Ext_tAir.Ext_tAir
          dr_RvAltMgt_uRvAltMes: data-element=R_RvAltMgt_uRvAltMes.RvAltMgt_uRvAltMes
          dr_Ext_idxCtlAltProvIdf: data-element=R_Ext_idxCtlAltProvIdf.Ext_idxCtlAltProvIdf
          dr_BatMgt_iBattMes: data-element=R_BatMgt_iBattMes.BatMgt_iBattMes
          dr_CoOptmEl_stOptmElCf: data-element=R_CoOptmEl_stOptmElCf.CoOptmEl_stOptmElCf
          dr_RvAltMgt_nRvAltMes: data-element=R_RvAltMgt_nRvAltMes.RvAltMgt_nRvAltMes
          dr_CoOptmEl_stPrevElProdReq: data-element=R_CoOptmEl_stPrevElProdReq.CoOptmEl_stPrevElProdReq
          dr_BatMgt_uBattMes: data-element=R_BatMgt_uBattMes.BatMgt_uBattMes
          dr_TqLimUH_grdLimVoltCtlDynMax: data-element=R_TqLimUH_grdLimVoltCtlDynMax.TqLimUH_grdLimVoltCtlDynMax
          dr_CoOptmEl_stStraVoltBatt: data-element=R_CoOptmEl_stStraVoltBatt.CoOptmEl_stStraVoltBatt
          dr_Ext_facRatTqAltCf: data-element=R_Ext_facRatTqAltCf.Ext_facRatTqAltCf
          dr_CoOptmEl_stOptmElStra: data-element=R_CoOptmEl_stOptmElStra.CoOptmEl_stOptmElStra
          dr_Ext_tCoMes: data-element=R_Ext_tCoMes.Ext_tCoMes
          dr_RvAltMgt_bIdcVldCurGenMod: data-element=R_RvAltMgt_bIdcVldCurGenMod.RvAltMgt_bIdcVldCurGenMod
          dr_CoOptmEl_grdPosSlop: data-element=R_CoOptmEl_grdPosSlop.CoOptmEl_grdPosSlop
          dr_Ext_iAltExct: data-element=R_Ext_iAltExct.Ext_iAltExct
          dr_BatMgt_tBattMes: data-element=R_BatMgt_tBattMes.BatMgt_tBattMes
          dr_CoOptmEl_uMax: data-element=R_CoOptmEl_uMax.CoOptmEl_uMax
          dr_Ext_stAltClasCf: data-element=R_Ext_stAltClasCf.Ext_stAltClasCf
          dr_CoOptmEl_rBattSoCSp: data-element=R_CoOptmEl_rBattSoCSp.CoOptmEl_rBattSoCSp
          dr_CoOptmEl_grdNegSlop: data-element=R_CoOptmEl_grdNegSlop.CoOptmEl_grdNegSlop
          dr_Ext_rAltCycOp: data-element=R_Ext_rAltCycOp.Ext_rAltCycOp
          dr_CoOptmEl_uMinInc: data-element=R_CoOptmEl_uMinInc.CoOptmEl_uMinInc
          dr_Ext_stElProdCf: data-element=R_Ext_stElProdCf.Ext_stElProdCf
        11 x data send point:
          ds_ElProdMgt_tqAltEstim: data-element=P_ElProdMgt_tqAltEstim.ElProdMgt_tqAltEstim
          ds_ElProdMgt_iExctMax: data-element=P_ElProdMgt_iExctMax.ElProdMgt_iExctMax
          ds_ElProdMgt_stProdPrgCh: data-element=P_ElProdMgt_stProdPrgCh.ElProdMgt_stProdPrgCh
          ds_ElProdMgt_stProdPrgChDi_nEng: data-element=P_ElProdMgt_stProdPrgChDi_nEng.ElProdMgt_stProdPrgChDi_nEng
          ds_ElProdMgt_uOfs_uElProdSp: data-element=P_ElProdMgt_uOfs_uElProdSp.ElProdMgt_uOfs_uElProdSp
          ds_ElProdMgt_uElProdSp: data-element=P_ElProdMgt_uElProdSp.ElProdMgt_uElProdSp
          ds_ElProdMgt_bAcvCoefFilDftAlt: data-element=P_ElProdMgt_bAcvCoefFilDftAlt.ElProdMgt_bAcvCoefFilDftAlt
          ds_ElProdMgt_uBattSp: data-element=P_ElProdMgt_uBattSp.ElProdMgt_uBattSp
          ds_ElProdMgt_rSoCErrEstim: data-element=P_ElProdMgt_rSoCErrEstim.ElProdMgt_rSoCErrEstim
          ds_ElProdMgt_uOfsLossCor: data-element=P_ElProdMgt_uOfsLossCor.ElProdMgt_uOfsLossCor
          ds_ElProdMgt_iAltEstim: data-element=P_ElProdMgt_iAltEstim.ElProdMgt_iAltEstim
        12 x sync call:
          ssp_FRM_bAcvElProdMgtStraDftMec: operation=R_FRM_bAcvElProdMgtStraDftMec.GetFunctionPermission
          ssp_FRM_bInhElProdMgtAltVoltSp: operation=R_FRM_bInhElProdMgtAltVoltSp.GetFunctionPermission
          ssp_FRM_bInhElProdMgtDiagCorLoss: operation=R_FRM_bInhElProdMgtDiagCorLoss.GetFunctionPermission
          ssp_ElProdMgt_CorLoss: operation=R_ElProdMgt_CorLoss.SetEventStatus
          ssp_FRM_bAcvElProdMgtStraDftEl: operation=R_FRM_bAcvElProdMgtStraDftEl.GetFunctionPermission
          ssp_FRM_bInhElProdMgtAltProvIdf: operation=R_FRM_bInhElProdMgtAltProvIdf.GetFunctionPermission
          ssp_FRM_bInhElProdMgtCorOfsLoss: operation=R_FRM_bInhElProdMgtCorOfsLoss.GetFunctionPermission
          ssp_ElProdMgt_CorSpCur: operation=R_ElProdMgt_CorSpCur.SetEventStatus
          ssp_FRM_bAcvElProdMgtStraDftCom: operation=R_FRM_bAcvElProdMgtStraDftCom.GetFunctionPermission
          ssp_FRM_bInhElProdMgtTqAltLoss: operation=R_FRM_bInhElProdMgtTqAltLoss.GetFunctionPermission
          ssp_FRM_bInhElProdMgtCorVoltSp: operation=R_FRM_bInhElProdMgtCorVoltSp.GetFunctionPermission
          ssp_FRM_bInhElProdMgtAltOfsSpMes: operation=R_FRM_bInhElProdMgtAltOfsSpMes.GetFunctionPermission
      RE_ProdElEm_005_MSE
        11 x data send point:
          ds_ElProdMgt_uOfsLossCor: data-element=P_ElProdMgt_uOfsLossCor.ElProdMgt_uOfsLossCor
          ds_ElProdMgt_rSoCErrEstim: data-element=P_ElProdMgt_rSoCErrEstim.ElProdMgt_rSoCErrEstim
          ds_ElProdMgt_stProdPrgCh: data-element=P_ElProdMgt_stProdPrgCh.ElProdMgt_stProdPrgCh
          ds_ElProdMgt_uOfs_uElProdSp: data-element=P_ElProdMgt_uOfs_uElProdSp.ElProdMgt_uOfs_uElProdSp
          ds_ElProdMgt_bAcvCoefFilDftAlt: data-element=P_ElProdMgt_bAcvCoefFilDftAlt.ElProdMgt_bAcvCoefFilDftAlt
          ds_ElProdMgt_uElProdSp: data-element=P_ElProdMgt_uElProdSp.ElProdMgt_uElProdSp
          ds_ElProdMgt_stProdPrgChDi_nEng: data-element=P_ElProdMgt_stProdPrgChDi_nEng.ElProdMgt_stProdPrgChDi_nEng
          ds_ElProdMgt_uBattSp: data-element=P_ElProdMgt_uBattSp.ElProdMgt_uBattSp
          ds_ElProdMgt_iExctMax: data-element=P_ElProdMgt_iExctMax.ElProdMgt_iExctMax
          ds_ElProdMgt_iAltEstim: data-element=P_ElProdMgt_iAltEstim.ElProdMgt_iAltEstim
          ds_ElProdMgt_tqAltEstim: data-element=P_ElProdMgt_tqAltEstim.ElProdMgt_tqAltEstim
      RE_ProdElEm_003_MSE
        40 x data send point:
          ds_BatMgt_ctStcAcvAntiAgiStra: data-element=P_BatMgt_ctStcAcvAntiAgiStra.BatMgt_ctStcAcvAntiAgiStra
          ds_BatMgt_grdNegSlopBattChProt: data-element=P_BatMgt_grdNegSlopBattChProt.BatMgt_grdNegSlopBattChProt
          ds_BatMgt_uReqEmMinBattTProt: data-element=P_BatMgt_uReqEmMinBattTProt.BatMgt_uReqEmMinBattTProt
          ds_BatMgt_bBattStopPrepAcvReq: data-element=P_BatMgt_bBattStopPrepAcvReq.BatMgt_bBattStopPrepAcvReq
          ds_BatMgt_uReqEmMaxBattTProt: data-element=P_BatMgt_uReqEmMaxBattTProt.BatMgt_uReqEmMaxBattTProt
          ds_BatMgt_tBattMes: data-element=P_BatMgt_tBattMes.BatMgt_tBattMes
          ds_BatMgt_rStcSoCMax: data-element=P_BatMgt_rStcSoCMax.BatMgt_rStcSoCMax
          ds_BatMgt_rSoCErrEstim: data-element=P_BatMgt_rSoCErrEstim.BatMgt_rSoCErrEstim
          ds_BatMgt_rStcSoCMin: data-element=P_BatMgt_rStcSoCMin.BatMgt_rStcSoCMin
          ds_BatMgt_rOfsSoC: data-element=P_BatMgt_rOfsSoC.BatMgt_rOfsSoC
          ds_BatMgt_rBattSoCCor: data-element=P_BatMgt_rBattSoCCor.BatMgt_rBattSoCCor
          ds_BatMgt_stBattSt: data-element=P_BatMgt_stBattSt.BatMgt_stBattSt
          ds_BatMgt_uReqEmMaxBattAntiAgi: data-element=P_BatMgt_uReqEmMaxBattAntiAgi.BatMgt_uReqEmMaxBattAntiAgi
          ds_BatMgt_stBattSoH: data-element=P_BatMgt_stBattSoH.BatMgt_stBattSoH
          ds_BatMgt_resBattIt: data-element=P_BatMgt_resBattIt.BatMgt_resBattIt
          ds_BatMgt_uBattStrt: data-element=P_BatMgt_uBattStrt.BatMgt_uBattStrt
          ds_BatMgt_grdNegSlopBattAntiAgi: data-element=P_BatMgt_grdNegSlopBattAntiAgi.BatMgt_grdNegSlopBattAntiAgi
          ds_BatMgt_uBattMes: data-element=P_BatMgt_uBattMes.BatMgt_uBattMes
          ds_BatMgt_bBattChProtAcvReq: data-element=P_BatMgt_bBattChProtAcvReq.BatMgt_bBattChProtAcvReq
          ds_BatMgt_uBattMinCkg: data-element=P_BatMgt_uBattMinCkg.BatMgt_uBattMinCkg
          ds_BatMgt_bAntiAgiStraEndIdc: data-element=P_BatMgt_bAntiAgiStraEndIdc.BatMgt_bAntiAgiStraEndIdc
          ds_BatMgt_grdPosSlopBattChProt: data-element=P_BatMgt_grdPosSlopBattChProt.BatMgt_grdPosSlopBattChProt
          ds_BatMgt_bBattAntiAgiAcvReq: data-element=P_BatMgt_bBattAntiAgiAcvReq.BatMgt_bBattAntiAgiAcvReq
          ds_BatMgt_ctStcCnclAntiAgiStra: data-element=P_BatMgt_ctStcCnclAntiAgiStra.BatMgt_ctStcCnclAntiAgiStra
          ds_BatMgt_iBattMes: data-element=P_BatMgt_iBattMes.BatMgt_iBattMes
          ds_BatMgt_grdPosSlopBattTProt: data-element=P_BatMgt_grdPosSlopBattTProt.BatMgt_grdPosSlopBattTProt
          ds_BatMgt_bBattTProtAcvReq: data-element=P_BatMgt_bBattTProtAcvReq.BatMgt_bBattTProtAcvReq
          ds_BatMgt_uBattRstrt: data-element=P_BatMgt_uBattRstrt.BatMgt_uBattRstrt
          ds_BatMgt_bAntiAgiStraEfcChIdc: data-element=P_BatMgt_bAntiAgiStraEfcChIdc.BatMgt_bAntiAgiStraEfcChIdc
          ds_BatMgt_grdNegSlopBattTProt: data-element=P_BatMgt_grdNegSlopBattTProt.BatMgt_grdNegSlopBattTProt
          ds_BatMgt_grdPosSlopBattAntiAgi: data-element=P_BatMgt_grdPosSlopBattAntiAgi.BatMgt_grdPosSlopBattAntiAgi
          ds_BatMgt_uReqEmMinBattChProt: data-element=P_BatMgt_uReqEmMinBattChProt.BatMgt_uReqEmMinBattChProt
          ds_BatMgt_uBattOc: data-element=P_BatMgt_uBattOc.BatMgt_uBattOc
          ds_BatMgt_bBattSoCMinProtAcvReq: data-element=P_BatMgt_bBattSoCMinProtAcvReq.BatMgt_bBattSoCMinProtAcvReq
          ds_BatMgt_uReqEmMinBattAntiAgi: data-element=P_BatMgt_uReqEmMinBattAntiAgi.BatMgt_uReqEmMinBattAntiAgi
          ds_BatMgt_iBattMaxCkg: data-element=P_BatMgt_iBattMaxCkg.BatMgt_iBattMaxCkg
          ds_BatMgt_tiStcVoltBattDmg: data-element=P_BatMgt_tiStcVoltBattDmg.BatMgt_tiStcVoltBattDmg
          ds_BatMgt_resBattItNorm: data-element=P_BatMgt_resBattItNorm.BatMgt_resBattItNorm
          ds_BatMgt_stBattSoC: data-element=P_BatMgt_stBattSoC.BatMgt_stBattSoC
          ds_BatMgt_uReqEmMaxBattChProt: data-element=P_BatMgt_uReqEmMaxBattChProt.BatMgt_uReqEmMaxBattChProt
  swc implementation Imp_ProdElEm: programming-language=C, behavior=IB_ProdElEm
    code-descriptors:
      code CodeDescriptor: type=SRC
        20 x xfile:
          ProdElEm_002_TEV_fct_c: url=ProdElEm_002_TEV_fct.c
          ProdElEm_nvm_c: url=ProdElEm_nvm.c
          ProdElEm_006_calibrations_h: url=ProdElEm_006_calibrations.h
          ProdElEm_004_TEV_fct_h: url=ProdElEm_004_TEV_fct.h
          ProdElEm_002_TEV_fct_h: url=ProdElEm_002_TEV_fct.h
          ProdElEm_006_TEV_fct_h: url=ProdElEm_006_TEV_fct.h
          ProdElEm_h: url=ProdElEm.h
          ProdElEm_afts_c: url=ProdElEm_afts.c
          ProdElEm_004_calibrations_c: url=ProdElEm_004_calibrations.c
          ProdElEm_006_TEV_fct_c: url=ProdElEm_006_TEV_fct.c
          ProdElEm_002_calibrations_h: url=ProdElEm_002_calibrations.h
          ProdElEm_004_TEV_fct_c: url=ProdElEm_004_TEV_fct.c
          ProdElEm_MemMap_h: url=ProdElEm_MemMap.h
          ProdElEm_004_calibrations_h: url=ProdElEm_004_calibrations.h
          ProdElEm_nvm_h: url=ProdElEm_nvm.h
          CoOptmEl_custom_h: url=CoOptmEl_custom.h
          ProdElEm_c: url=ProdElEm.c
          ProdElEm_002_calibrations_c: url=ProdElEm_002_calibrations.c
          ProdElEm_006_calibrations_c: url=ProdElEm_006_calibrations.c
          CoOptmEl_custom_c: url=CoOptmEl_custom.c
